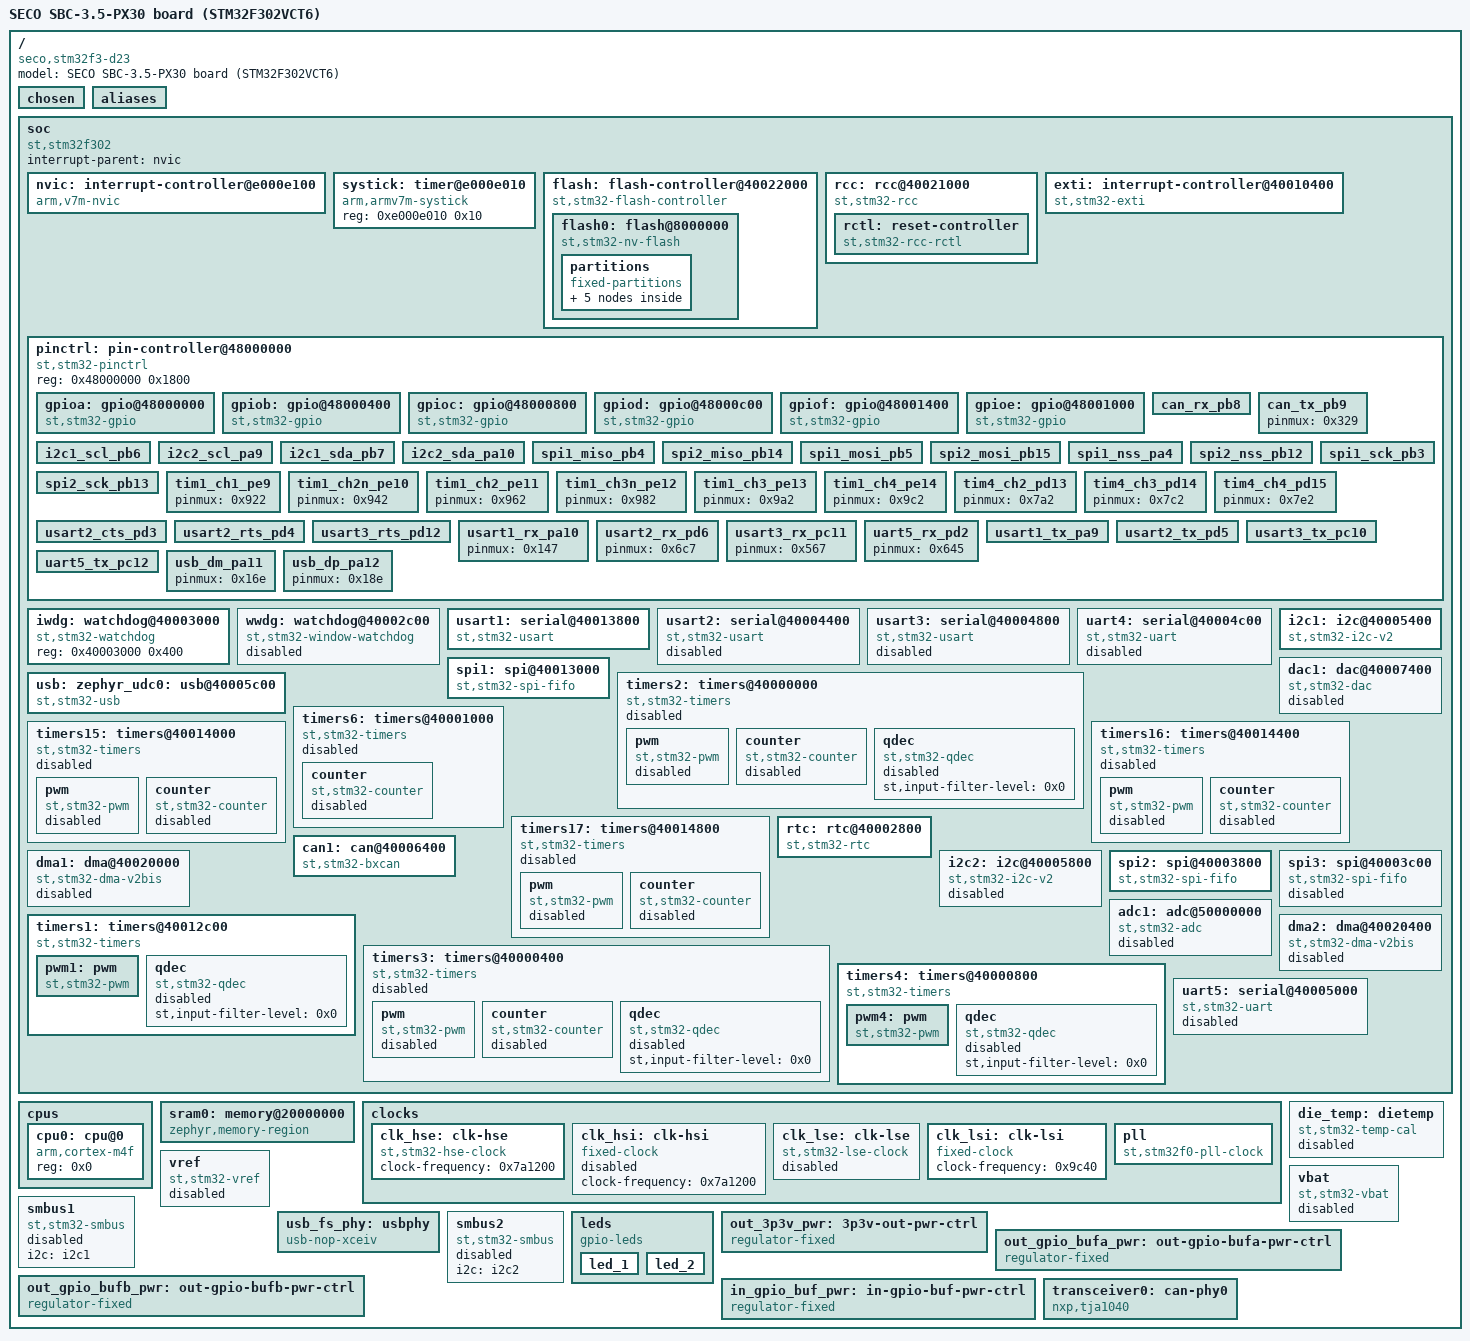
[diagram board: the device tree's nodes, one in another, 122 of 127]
/dts-v1/;

/* node '/' defined in zephyr/dts/common/skeleton.dtsi:9 */
/ {
	#address-cells = < 0x1 >;                          /* in zephyr/dts/common/skeleton.dtsi:10 */
	#size-cells = < 0x1 >;                             /* in zephyr/dts/common/skeleton.dtsi:11 */
	model = "SECO SBC-3.5-PX30 board (STM32F302VCT6)"; /* in zephyr/boards/seco/stm32f3_seco_d23/stm32f3_seco_d23.dts:12 */
	compatible = "seco,stm32f3-d23";                   /* in zephyr/boards/seco/stm32f3_seco_d23/stm32f3_seco_d23.dts:13 */

	/* node '/chosen' defined in zephyr/dts/common/skeleton.dtsi:13 */
	chosen {
		zephyr,flash-controller = &flash;         /* in zephyr/dts/arm/st/f3/stm32f3.dtsi:24 */
		zephyr,console = &usart1;                 /* in zephyr/boards/seco/stm32f3_seco_d23/stm32f3_seco_d23.dts:16 */
		zephyr,code-partition = &slot0_partition; /* in zephyr/boards/seco/stm32f3_seco_d23/stm32f3_seco_d23.dts:17 */
		zephyr,shell-uart = &usart1;              /* in zephyr/boards/seco/stm32f3_seco_d23/stm32f3_seco_d23.dts:18 */
		zephyr,sram = &sram0;                     /* in zephyr/boards/seco/stm32f3_seco_d23/stm32f3_seco_d23.dts:19 */
		zephyr,flash = &flash0;                   /* in zephyr/boards/seco/stm32f3_seco_d23/stm32f3_seco_d23.dts:20 */
		zephyr,canbus = &can1;                    /* in zephyr/boards/seco/stm32f3_seco_d23/stm32f3_seco_d23.dts:21 */
	};

	/* node '/aliases' defined in zephyr/dts/common/skeleton.dtsi:15 */
	aliases {
		led0 = &led_1; /* in zephyr/boards/seco/stm32f3_seco_d23/stm32f3_seco_d23.dts:79 */
		led1 = &led_2; /* in zephyr/boards/seco/stm32f3_seco_d23/stm32f3_seco_d23.dts:80 */
	};

	/* node '/soc' defined in zephyr/dts/arm/armv7-m.dtsi:6 */
	soc {
		#address-cells = < 0x1 >;     /* in zephyr/dts/arm/armv7-m.dtsi:7 */
		#size-cells = < 0x1 >;        /* in zephyr/dts/arm/armv7-m.dtsi:8 */
		interrupt-parent = < &nvic >; /* in zephyr/dts/arm/armv7-m.dtsi:10 */
		ranges;                       /* in zephyr/dts/arm/armv7-m.dtsi:11 */
		compatible = "st,stm32f302",
		             "st,stm32f3",
		             "simple-bus";    /* in zephyr/dts/arm/st/f3/stm32f302.dtsi:12 */

		/* node '/soc/interrupt-controller@e000e100' defined in zephyr/dts/arm/armv7-m.dtsi:13 */
		nvic: interrupt-controller@e000e100 {
			#address-cells = < 0x1 >;            /* in zephyr/dts/arm/armv7-m.dtsi:14 */
			compatible = "arm,v7m-nvic";         /* in zephyr/dts/arm/armv7-m.dtsi:15 */
			reg = < 0xe000e100 0xc00 >;          /* in zephyr/dts/arm/armv7-m.dtsi:16 */
			interrupt-controller;                /* in zephyr/dts/arm/armv7-m.dtsi:17 */
			#interrupt-cells = < 0x2 >;          /* in zephyr/dts/arm/armv7-m.dtsi:18 */
			arm,num-irq-priority-bits = < 0x4 >; /* in zephyr/dts/arm/st/f3/stm32f3.dtsi:456 */
			phandle = < 0x1 >;                   /* in zephyr/dts/arm/armv7-m.dtsi:10 */
		};

		/* node '/soc/timer@e000e010' defined in zephyr/dts/arm/armv7-m.dtsi:21 */
		systick: timer@e000e010 {
			compatible = "arm,armv7m-systick"; /* in zephyr/dts/arm/armv7-m.dtsi:22 */
			reg = < 0xe000e010 0x10 >;         /* in zephyr/dts/arm/armv7-m.dtsi:23 */
		};

		/* node '/soc/flash-controller@40022000' defined in zephyr/dts/arm/st/f3/stm32f3.dtsi:80 */
		flash: flash-controller@40022000 {
			compatible = "st,stm32-flash-controller",
			             "st,stm32f1-flash-controller"; /* in zephyr/dts/arm/st/f3/stm32f3.dtsi:81 */
			reg = < 0x40022000 0x400 >;                 /* in zephyr/dts/arm/st/f3/stm32f3.dtsi:82 */
			interrupts = < 0x4 0x0 >;                   /* in zephyr/dts/arm/st/f3/stm32f3.dtsi:83 */
			clocks = < &rcc 0x14 0x10 >;                /* in zephyr/dts/arm/st/f3/stm32f3.dtsi:84 */
			#address-cells = < 0x1 >;                   /* in zephyr/dts/arm/st/f3/stm32f3.dtsi:86 */
			#size-cells = < 0x1 >;                      /* in zephyr/dts/arm/st/f3/stm32f3.dtsi:87 */

			/* node '/soc/flash-controller@40022000/flash@8000000' defined in zephyr/dts/arm/st/f3/stm32f3.dtsi:89 */
			flash0: flash@8000000 {
				compatible = "st,stm32-nv-flash",
				             "soc-nv-flash";      /* in zephyr/dts/arm/st/f3/stm32f3.dtsi:90 */
				write-block-size = < 0x2 >;       /* in zephyr/dts/arm/st/f3/stm32f3.dtsi:92 */
				erase-block-size = < 0x800 >;     /* in zephyr/dts/arm/st/f3/stm32f3.dtsi:93 */
				max-erase-time = < 0x28 >;        /* in zephyr/dts/arm/st/f3/stm32f3.dtsi:95 */
				reg = < 0x8000000 0x40000 >;      /* in zephyr/dts/arm/st/f3/stm32f302Xc.dtsi:18 */

				/* node '/soc/flash-controller@40022000/flash@8000000/partitions' defined in zephyr/boards/seco/stm32f3_seco_d23/stm32f3_seco_d23.dts:187 */
				partitions {
					compatible = "fixed-partitions"; /* in zephyr/boards/seco/stm32f3_seco_d23/stm32f3_seco_d23.dts:188 */
					#address-cells = < 0x1 >;        /* in zephyr/boards/seco/stm32f3_seco_d23/stm32f3_seco_d23.dts:189 */
					#size-cells = < 0x1 >;           /* in zephyr/boards/seco/stm32f3_seco_d23/stm32f3_seco_d23.dts:190 */

					/* node '/soc/flash-controller@40022000/flash@8000000/partitions/partition@0' defined in zephyr/boards/seco/stm32f3_seco_d23/stm32f3_seco_d23.dts:192 */
					boot_partition: partition@0 {
						label = "mcuboot";     /* in zephyr/boards/seco/stm32f3_seco_d23/stm32f3_seco_d23.dts:193 */
						reg = < 0x0 0x10000 >; /* in zephyr/boards/seco/stm32f3_seco_d23/stm32f3_seco_d23.dts:194 */
						read-only;             /* in zephyr/boards/seco/stm32f3_seco_d23/stm32f3_seco_d23.dts:195 */
					};

					/* node '/soc/flash-controller@40022000/flash@8000000/partitions/partition@20000' defined in zephyr/boards/seco/stm32f3_seco_d23/stm32f3_seco_d23.dts:203 */
					slot0_partition: partition@20000 {
						label = "image-0";        /* in zephyr/boards/seco/stm32f3_seco_d23/stm32f3_seco_d23.dts:204 */
						reg = < 0x20000 0x8000 >; /* in zephyr/boards/seco/stm32f3_seco_d23/stm32f3_seco_d23.dts:205 */
					};

					/* node '/soc/flash-controller@40022000/flash@8000000/partitions/partition@28000' defined in zephyr/boards/seco/stm32f3_seco_d23/stm32f3_seco_d23.dts:208 */
					slot1_partition: partition@28000 {
						label = "image-1";        /* in zephyr/boards/seco/stm32f3_seco_d23/stm32f3_seco_d23.dts:209 */
						reg = < 0x28000 0x8000 >; /* in zephyr/boards/seco/stm32f3_seco_d23/stm32f3_seco_d23.dts:210 */
					};

					/* node '/soc/flash-controller@40022000/flash@8000000/partitions/partition@30000' defined in zephyr/boards/seco/stm32f3_seco_d23/stm32f3_seco_d23.dts:213 */
					storage_partition: partition@30000 {
						label = "storage";        /* in zephyr/boards/seco/stm32f3_seco_d23/stm32f3_seco_d23.dts:214 */
						reg = < 0x30000 0x2000 >; /* in zephyr/boards/seco/stm32f3_seco_d23/stm32f3_seco_d23.dts:215 */
					};

					/* node '/soc/flash-controller@40022000/flash@8000000/partitions/partition@32000' defined in zephyr/boards/seco/stm32f3_seco_d23/stm32f3_seco_d23.dts:218 */
					scratch_partition: partition@32000 {
						label = "image-scratch";  /* in zephyr/boards/seco/stm32f3_seco_d23/stm32f3_seco_d23.dts:219 */
						reg = < 0x32000 0x8000 >; /* in zephyr/boards/seco/stm32f3_seco_d23/stm32f3_seco_d23.dts:220 */
					};
				};
			};
		};

		/* node '/soc/rcc@40021000' defined in zephyr/dts/arm/st/f3/stm32f3.dtsi:99 */
		rcc: rcc@40021000 {
			compatible = "st,stm32-rcc";     /* in zephyr/dts/arm/st/f3/stm32f3.dtsi:100 */
			#clock-cells = < 0x2 >;          /* in zephyr/dts/arm/st/f3/stm32f3.dtsi:101 */
			reg = < 0x40021000 0x400 >;      /* in zephyr/dts/arm/st/f3/stm32f3.dtsi:102 */
			clocks = < &pll >;               /* in zephyr/boards/seco/stm32f3_seco_d23/stm32f3_seco_d23.dts:101 */
			clock-frequency = < 0x44aa200 >; /* in zephyr/boards/seco/stm32f3_seco_d23/stm32f3_seco_d23.dts:102 */
			ahb-prescaler = < 0x1 >;         /* in zephyr/boards/seco/stm32f3_seco_d23/stm32f3_seco_d23.dts:103 */
			apb1-prescaler = < 0x2 >;        /* in zephyr/boards/seco/stm32f3_seco_d23/stm32f3_seco_d23.dts:104 */
			apb2-prescaler = < 0x1 >;        /* in zephyr/boards/seco/stm32f3_seco_d23/stm32f3_seco_d23.dts:105 */
			status = "okay";                 /* in zephyr/boards/seco/stm32f3_seco_d23/stm32f3_seco_d23.dts:106 */
			phandle = < 0x2 >;               /* in zephyr/dts/arm/st/f3/stm32f3.dtsi:84 */

			/* node '/soc/rcc@40021000/reset-controller' defined in zephyr/dts/arm/st/f3/stm32f3.dtsi:104 */
			rctl: reset-controller {
				compatible = "st,stm32-rcc-rctl"; /* in zephyr/dts/arm/st/f3/stm32f3.dtsi:105 */
				#reset-cells = < 0x1 >;           /* in zephyr/dts/arm/st/f3/stm32f3.dtsi:106 */
				phandle = < 0x4 >;                /* in zephyr/dts/arm/st/f3/stm32f3.dtsi:191 */
			};
		};

		/* node '/soc/interrupt-controller@40010400' defined in zephyr/dts/arm/st/f3/stm32f3.dtsi:110 */
		exti: interrupt-controller@40010400 {
			compatible = "st,stm32-exti";  /* in zephyr/dts/arm/st/f3/stm32f3.dtsi:111 */
			interrupt-controller;          /* in zephyr/dts/arm/st/f3/stm32f3.dtsi:112 */
			#interrupt-cells = < 0x1 >;    /* in zephyr/dts/arm/st/f3/stm32f3.dtsi:113 */
			#address-cells = < 0x0 >;      /* in zephyr/dts/arm/st/f3/stm32f3.dtsi:114 */
			reg = < 0x40010400 0x400 >;    /* in zephyr/dts/arm/st/f3/stm32f3.dtsi:115 */
			clocks = < &rcc 0x18 0x1 >;    /* in zephyr/dts/arm/st/f3/stm32f3.dtsi:116 */
			num-lines = < 0x20 >;          /* in zephyr/dts/arm/st/f3/stm32f3.dtsi:117 */
			interrupts = < 0x6 0x0 >,
			             < 0x7 0x0 >,
			             < 0x8 0x0 >,
			             < 0x9 0x0 >,
			             < 0xa 0x0 >,
			             < 0x17 0x0 >,
			             < 0x28 0x0 >;     /* in zephyr/dts/arm/st/f3/stm32f3.dtsi:118 */
			interrupt-names = "line0",
			                  "line1",
			                  "line2",
			                  "line3",
			                  "line4",
			                  "line5-9",
			                  "line10-15"; /* in zephyr/dts/arm/st/f3/stm32f3.dtsi:120 */
			line-ranges = < 0x0 0x1 >,
			              < 0x1 0x1 >,
			              < 0x2 0x1 >,
			              < 0x3 0x1 >,
			              < 0x4 0x1 >,
			              < 0x5 0x5 >,
			              < 0xa 0x6 >;     /* in zephyr/dts/arm/st/f3/stm32f3.dtsi:122 */
		};

		/* node '/soc/pin-controller@48000000' defined in zephyr/dts/arm/st/f3/stm32f3.dtsi:126 */
		pinctrl: pin-controller@48000000 {
			compatible = "st,stm32-pinctrl"; /* in zephyr/dts/arm/st/f3/stm32f3.dtsi:127 */
			#address-cells = < 0x1 >;        /* in zephyr/dts/arm/st/f3/stm32f3.dtsi:128 */
			#size-cells = < 0x1 >;           /* in zephyr/dts/arm/st/f3/stm32f3.dtsi:129 */
			reg = < 0x48000000 0x1800 >;     /* in zephyr/dts/arm/st/f3/stm32f3.dtsi:130 */

			/* node '/soc/pin-controller@48000000/gpio@48000000' defined in zephyr/dts/arm/st/f3/stm32f3.dtsi:132 */
			gpioa: gpio@48000000 {
				compatible = "st,stm32-gpio";   /* in zephyr/dts/arm/st/f3/stm32f3.dtsi:133 */
				gpio-controller;                /* in zephyr/dts/arm/st/f3/stm32f3.dtsi:134 */
				#gpio-cells = < 0x2 >;          /* in zephyr/dts/arm/st/f3/stm32f3.dtsi:135 */
				reg = < 0x48000000 0x400 >;     /* in zephyr/dts/arm/st/f3/stm32f3.dtsi:136 */
				clocks = < &rcc 0x14 0x20000 >; /* in zephyr/dts/arm/st/f3/stm32f3.dtsi:137 */
			};

			/* node '/soc/pin-controller@48000000/gpio@48000400' defined in zephyr/dts/arm/st/f3/stm32f3.dtsi:140 */
			gpiob: gpio@48000400 {
				compatible = "st,stm32-gpio";   /* in zephyr/dts/arm/st/f3/stm32f3.dtsi:141 */
				gpio-controller;                /* in zephyr/dts/arm/st/f3/stm32f3.dtsi:142 */
				#gpio-cells = < 0x2 >;          /* in zephyr/dts/arm/st/f3/stm32f3.dtsi:143 */
				reg = < 0x48000400 0x400 >;     /* in zephyr/dts/arm/st/f3/stm32f3.dtsi:144 */
				clocks = < &rcc 0x14 0x40000 >; /* in zephyr/dts/arm/st/f3/stm32f3.dtsi:145 */
			};

			/* node '/soc/pin-controller@48000000/gpio@48000800' defined in zephyr/dts/arm/st/f3/stm32f3.dtsi:148 */
			gpioc: gpio@48000800 {
				compatible = "st,stm32-gpio";   /* in zephyr/dts/arm/st/f3/stm32f3.dtsi:149 */
				gpio-controller;                /* in zephyr/dts/arm/st/f3/stm32f3.dtsi:150 */
				#gpio-cells = < 0x2 >;          /* in zephyr/dts/arm/st/f3/stm32f3.dtsi:151 */
				reg = < 0x48000800 0x400 >;     /* in zephyr/dts/arm/st/f3/stm32f3.dtsi:152 */
				clocks = < &rcc 0x14 0x80000 >; /* in zephyr/dts/arm/st/f3/stm32f3.dtsi:153 */
			};

			/* node '/soc/pin-controller@48000000/gpio@48000c00' defined in zephyr/dts/arm/st/f3/stm32f3.dtsi:156 */
			gpiod: gpio@48000c00 {
				compatible = "st,stm32-gpio";    /* in zephyr/dts/arm/st/f3/stm32f3.dtsi:157 */
				gpio-controller;                 /* in zephyr/dts/arm/st/f3/stm32f3.dtsi:158 */
				#gpio-cells = < 0x2 >;           /* in zephyr/dts/arm/st/f3/stm32f3.dtsi:159 */
				reg = < 0x48000c00 0x400 >;      /* in zephyr/dts/arm/st/f3/stm32f3.dtsi:160 */
				clocks = < &rcc 0x14 0x100000 >; /* in zephyr/dts/arm/st/f3/stm32f3.dtsi:161 */
				phandle = < 0x2f >;              /* in zephyr/boards/seco/stm32f3_seco_d23/stm32f3_seco_d23.dts:28 */
			};

			/* node '/soc/pin-controller@48000000/gpio@48001400' defined in zephyr/dts/arm/st/f3/stm32f3.dtsi:164 */
			gpiof: gpio@48001400 {
				compatible = "st,stm32-gpio";    /* in zephyr/dts/arm/st/f3/stm32f3.dtsi:165 */
				gpio-controller;                 /* in zephyr/dts/arm/st/f3/stm32f3.dtsi:166 */
				#gpio-cells = < 0x2 >;           /* in zephyr/dts/arm/st/f3/stm32f3.dtsi:167 */
				reg = < 0x48001400 0x400 >;      /* in zephyr/dts/arm/st/f3/stm32f3.dtsi:168 */
				clocks = < &rcc 0x14 0x400000 >; /* in zephyr/dts/arm/st/f3/stm32f3.dtsi:169 */
				phandle = < 0x31 >;              /* in zephyr/boards/seco/stm32f3_seco_d23/stm32f3_seco_d23.dts:50 */
			};

			/* node '/soc/pin-controller@48000000/gpio@48001000' defined in zephyr/dts/arm/st/f3/stm32f302Xc.dtsi:98 */
			gpioe: gpio@48001000 {
				compatible = "st,stm32-gpio";    /* in zephyr/dts/arm/st/f3/stm32f302Xc.dtsi:99 */
				gpio-controller;                 /* in zephyr/dts/arm/st/f3/stm32f302Xc.dtsi:100 */
				#gpio-cells = < 0x2 >;           /* in zephyr/dts/arm/st/f3/stm32f302Xc.dtsi:101 */
				reg = < 0x48001000 0x400 >;      /* in zephyr/dts/arm/st/f3/stm32f302Xc.dtsi:102 */
				clocks = < &rcc 0x14 0x200000 >; /* in zephyr/dts/arm/st/f3/stm32f302Xc.dtsi:103 */
				phandle = < 0x30 >;              /* in zephyr/boards/seco/stm32f3_seco_d23/stm32f3_seco_d23.dts:41 */
			};

			/* node '/soc/pin-controller@48000000/can_rx_pb8' defined in modules/hal/stm32/dts/st/f3/stm32f302v(b-c)tx-pinctrl.dtsi:460 */
			can_rx_pb8: can_rx_pb8 {
				pinmux = < 0x309 >; /* in modules/hal/stm32/dts/st/f3/stm32f302v(b-c)tx-pinctrl.dtsi:461 */
				bias-pull-up;       /* in modules/hal/stm32/dts/st/f3/stm32f302v(b-c)tx-pinctrl.dtsi:462 */
				phandle = < 0x17 >; /* in zephyr/boards/seco/stm32f3_seco_d23/stm32f3_seco_d23.dts:180 */
			};

			/* node '/soc/pin-controller@48000000/can_tx_pb9' defined in modules/hal/stm32/dts/st/f3/stm32f302v(b-c)tx-pinctrl.dtsi:476 */
			can_tx_pb9: can_tx_pb9 {
				pinmux = < 0x329 >; /* in modules/hal/stm32/dts/st/f3/stm32f302v(b-c)tx-pinctrl.dtsi:477 */
				phandle = < 0x18 >; /* in zephyr/boards/seco/stm32f3_seco_d23/stm32f3_seco_d23.dts:180 */
			};

			/* node '/soc/pin-controller@48000000/i2c1_scl_pb6' defined in modules/hal/stm32/dts/st/f3/stm32f302v(b-c)tx-pinctrl.dtsi:634 */
			i2c1_scl_pb6: i2c1_scl_pb6 {
				pinmux = < 0x2c4 >; /* in modules/hal/stm32/dts/st/f3/stm32f302v(b-c)tx-pinctrl.dtsi:635 */
				bias-pull-up;       /* in modules/hal/stm32/dts/st/f3/stm32f302v(b-c)tx-pinctrl.dtsi:636 */
				drive-open-drain;   /* in modules/hal/stm32/dts/st/f3/stm32f302v(b-c)tx-pinctrl.dtsi:637 */
				phandle = < 0xe >;  /* in zephyr/boards/seco/stm32f3_seco_d23/stm32f3_seco_d23.dts:140 */
			};

			/* node '/soc/pin-controller@48000000/i2c2_scl_pa9' defined in modules/hal/stm32/dts/st/f3/stm32f302v(b-c)tx-pinctrl.dtsi:646 */
			i2c2_scl_pa9: i2c2_scl_pa9 {
				pinmux = < 0x124 >; /* in modules/hal/stm32/dts/st/f3/stm32f302v(b-c)tx-pinctrl.dtsi:647 */
				bias-pull-up;       /* in modules/hal/stm32/dts/st/f3/stm32f302v(b-c)tx-pinctrl.dtsi:648 */
				drive-open-drain;   /* in modules/hal/stm32/dts/st/f3/stm32f302v(b-c)tx-pinctrl.dtsi:649 */
				phandle = < 0x1a >; /* in zephyr/boards/seco/stm32f3_seco_d23/stm32f3_seco_d23.dts:148 */
			};

			/* node '/soc/pin-controller@48000000/i2c1_sda_pb7' defined in modules/hal/stm32/dts/st/f3/stm32f302v(b-c)tx-pinctrl.dtsi:672 */
			i2c1_sda_pb7: i2c1_sda_pb7 {
				pinmux = < 0x2e4 >; /* in modules/hal/stm32/dts/st/f3/stm32f302v(b-c)tx-pinctrl.dtsi:673 */
				bias-pull-up;       /* in modules/hal/stm32/dts/st/f3/stm32f302v(b-c)tx-pinctrl.dtsi:674 */
				drive-open-drain;   /* in modules/hal/stm32/dts/st/f3/stm32f302v(b-c)tx-pinctrl.dtsi:675 */
				phandle = < 0xf >;  /* in zephyr/boards/seco/stm32f3_seco_d23/stm32f3_seco_d23.dts:140 */
			};

			/* node '/soc/pin-controller@48000000/i2c2_sda_pa10' defined in modules/hal/stm32/dts/st/f3/stm32f302v(b-c)tx-pinctrl.dtsi:684 */
			i2c2_sda_pa10: i2c2_sda_pa10 {
				pinmux = < 0x144 >; /* in modules/hal/stm32/dts/st/f3/stm32f302v(b-c)tx-pinctrl.dtsi:685 */
				bias-pull-up;       /* in modules/hal/stm32/dts/st/f3/stm32f302v(b-c)tx-pinctrl.dtsi:686 */
				drive-open-drain;   /* in modules/hal/stm32/dts/st/f3/stm32f302v(b-c)tx-pinctrl.dtsi:687 */
				phandle = < 0x1b >; /* in zephyr/boards/seco/stm32f3_seco_d23/stm32f3_seco_d23.dts:148 */
			};

			/* node '/soc/pin-controller@48000000/spi1_miso_pb4' defined in modules/hal/stm32/dts/st/f3/stm32f302v(b-c)tx-pinctrl.dtsi:874 */
			spi1_miso_pb4: spi1_miso_pb4 {
				pinmux = < 0x285 >; /* in modules/hal/stm32/dts/st/f3/stm32f302v(b-c)tx-pinctrl.dtsi:875 */
				bias-pull-down;     /* in modules/hal/stm32/dts/st/f3/stm32f302v(b-c)tx-pinctrl.dtsi:876 */
				phandle = < 0x12 >; /* in zephyr/boards/seco/stm32f3_seco_d23/stm32f3_seco_d23.dts:154 */
			};

			/* node '/soc/pin-controller@48000000/spi2_miso_pb14' defined in modules/hal/stm32/dts/st/f3/stm32f302v(b-c)tx-pinctrl.dtsi:879 */
			spi2_miso_pb14: spi2_miso_pb14 {
				pinmux = < 0x3c5 >; /* in modules/hal/stm32/dts/st/f3/stm32f302v(b-c)tx-pinctrl.dtsi:880 */
				bias-pull-down;     /* in modules/hal/stm32/dts/st/f3/stm32f302v(b-c)tx-pinctrl.dtsi:881 */
				phandle = < 0x1e >; /* in zephyr/boards/seco/stm32f3_seco_d23/stm32f3_seco_d23.dts:161 */
			};

			/* node '/soc/pin-controller@48000000/spi1_mosi_pb5' defined in modules/hal/stm32/dts/st/f3/stm32f302v(b-c)tx-pinctrl.dtsi:901 */
			spi1_mosi_pb5: spi1_mosi_pb5 {
				pinmux = < 0x2a5 >; /* in modules/hal/stm32/dts/st/f3/stm32f302v(b-c)tx-pinctrl.dtsi:902 */
				bias-pull-down;     /* in modules/hal/stm32/dts/st/f3/stm32f302v(b-c)tx-pinctrl.dtsi:903 */
				phandle = < 0x13 >; /* in zephyr/boards/seco/stm32f3_seco_d23/stm32f3_seco_d23.dts:154 */
			};

			/* node '/soc/pin-controller@48000000/spi2_mosi_pb15' defined in modules/hal/stm32/dts/st/f3/stm32f302v(b-c)tx-pinctrl.dtsi:906 */
			spi2_mosi_pb15: spi2_mosi_pb15 {
				pinmux = < 0x3e5 >; /* in modules/hal/stm32/dts/st/f3/stm32f302v(b-c)tx-pinctrl.dtsi:907 */
				bias-pull-down;     /* in modules/hal/stm32/dts/st/f3/stm32f302v(b-c)tx-pinctrl.dtsi:908 */
				phandle = < 0x1f >; /* in zephyr/boards/seco/stm32f3_seco_d23/stm32f3_seco_d23.dts:161 */
			};

			/* node '/soc/pin-controller@48000000/spi1_nss_pa4' defined in modules/hal/stm32/dts/st/f3/stm32f302v(b-c)tx-pinctrl.dtsi:923 */
			spi1_nss_pa4: spi1_nss_pa4 {
				pinmux = < 0x85 >;  /* in modules/hal/stm32/dts/st/f3/stm32f302v(b-c)tx-pinctrl.dtsi:924 */
				bias-pull-up;       /* in modules/hal/stm32/dts/st/f3/stm32f302v(b-c)tx-pinctrl.dtsi:925 */
				phandle = < 0x10 >; /* in zephyr/boards/seco/stm32f3_seco_d23/stm32f3_seco_d23.dts:154 */
			};

			/* node '/soc/pin-controller@48000000/spi2_nss_pb12' defined in modules/hal/stm32/dts/st/f3/stm32f302v(b-c)tx-pinctrl.dtsi:933 */
			spi2_nss_pb12: spi2_nss_pb12 {
				pinmux = < 0x385 >; /* in modules/hal/stm32/dts/st/f3/stm32f302v(b-c)tx-pinctrl.dtsi:934 */
				bias-pull-up;       /* in modules/hal/stm32/dts/st/f3/stm32f302v(b-c)tx-pinctrl.dtsi:935 */
				phandle = < 0x1c >; /* in zephyr/boards/seco/stm32f3_seco_d23/stm32f3_seco_d23.dts:161 */
			};

			/* node '/soc/pin-controller@48000000/spi1_sck_pb3' defined in modules/hal/stm32/dts/st/f3/stm32f302v(b-c)tx-pinctrl.dtsi:961 */
			spi1_sck_pb3: spi1_sck_pb3 {
				pinmux = < 0x265 >;            /* in modules/hal/stm32/dts/st/f3/stm32f302v(b-c)tx-pinctrl.dtsi:962 */
				bias-pull-down;                /* in modules/hal/stm32/dts/st/f3/stm32f302v(b-c)tx-pinctrl.dtsi:963 */
				slew-rate = "very-high-speed"; /* in modules/hal/stm32/dts/st/f3/stm32f302v(b-c)tx-pinctrl.dtsi:964 */
				phandle = < 0x11 >;            /* in zephyr/boards/seco/stm32f3_seco_d23/stm32f3_seco_d23.dts:154 */
			};

			/* node '/soc/pin-controller@48000000/spi2_sck_pb13' defined in modules/hal/stm32/dts/st/f3/stm32f302v(b-c)tx-pinctrl.dtsi:967 */
			spi2_sck_pb13: spi2_sck_pb13 {
				pinmux = < 0x3a5 >;            /* in modules/hal/stm32/dts/st/f3/stm32f302v(b-c)tx-pinctrl.dtsi:968 */
				bias-pull-down;                /* in modules/hal/stm32/dts/st/f3/stm32f302v(b-c)tx-pinctrl.dtsi:969 */
				slew-rate = "very-high-speed"; /* in modules/hal/stm32/dts/st/f3/stm32f302v(b-c)tx-pinctrl.dtsi:970 */
				phandle = < 0x1d >;            /* in zephyr/boards/seco/stm32f3_seco_d23/stm32f3_seco_d23.dts:161 */
			};

			/* node '/soc/pin-controller@48000000/tim1_ch1_pe9' defined in modules/hal/stm32/dts/st/f3/stm32f302v(b-c)tx-pinctrl.dtsi:1109 */
			tim1_ch1_pe9: tim1_ch1_pe9 {
				pinmux = < 0x922 >; /* in modules/hal/stm32/dts/st/f3/stm32f302v(b-c)tx-pinctrl.dtsi:1110 */
				phandle = < 0x20 >; /* in zephyr/boards/seco/stm32f3_seco_d23/stm32f3_seco_d23.dts:234 */
			};

			/* node '/soc/pin-controller@48000000/tim1_ch2n_pe10' defined in modules/hal/stm32/dts/st/f3/stm32f302v(b-c)tx-pinctrl.dtsi:1113 */
			tim1_ch2n_pe10: tim1_ch2n_pe10 {
				pinmux = < 0x942 >; /* in modules/hal/stm32/dts/st/f3/stm32f302v(b-c)tx-pinctrl.dtsi:1114 */
				phandle = < 0x21 >; /* in zephyr/boards/seco/stm32f3_seco_d23/stm32f3_seco_d23.dts:234 */
			};

			/* node '/soc/pin-controller@48000000/tim1_ch2_pe11' defined in modules/hal/stm32/dts/st/f3/stm32f302v(b-c)tx-pinctrl.dtsi:1117 */
			tim1_ch2_pe11: tim1_ch2_pe11 {
				pinmux = < 0x962 >; /* in modules/hal/stm32/dts/st/f3/stm32f302v(b-c)tx-pinctrl.dtsi:1118 */
				phandle = < 0x22 >; /* in zephyr/boards/seco/stm32f3_seco_d23/stm32f3_seco_d23.dts:234 */
			};

			/* node '/soc/pin-controller@48000000/tim1_ch3n_pe12' defined in modules/hal/stm32/dts/st/f3/stm32f302v(b-c)tx-pinctrl.dtsi:1121 */
			tim1_ch3n_pe12: tim1_ch3n_pe12 {
				pinmux = < 0x982 >; /* in modules/hal/stm32/dts/st/f3/stm32f302v(b-c)tx-pinctrl.dtsi:1122 */
				phandle = < 0x23 >; /* in zephyr/boards/seco/stm32f3_seco_d23/stm32f3_seco_d23.dts:234 */
			};

			/* node '/soc/pin-controller@48000000/tim1_ch3_pe13' defined in modules/hal/stm32/dts/st/f3/stm32f302v(b-c)tx-pinctrl.dtsi:1125 */
			tim1_ch3_pe13: tim1_ch3_pe13 {
				pinmux = < 0x9a2 >; /* in modules/hal/stm32/dts/st/f3/stm32f302v(b-c)tx-pinctrl.dtsi:1126 */
				phandle = < 0x24 >; /* in zephyr/boards/seco/stm32f3_seco_d23/stm32f3_seco_d23.dts:234 */
			};

			/* node '/soc/pin-controller@48000000/tim1_ch4_pe14' defined in modules/hal/stm32/dts/st/f3/stm32f302v(b-c)tx-pinctrl.dtsi:1129 */
			tim1_ch4_pe14: tim1_ch4_pe14 {
				pinmux = < 0x9c2 >; /* in modules/hal/stm32/dts/st/f3/stm32f302v(b-c)tx-pinctrl.dtsi:1130 */
				phandle = < 0x25 >; /* in zephyr/boards/seco/stm32f3_seco_d23/stm32f3_seco_d23.dts:234 */
			};

			/* node '/soc/pin-controller@48000000/tim4_ch2_pd13' defined in modules/hal/stm32/dts/st/f3/stm32f302v(b-c)tx-pinctrl.dtsi:1293 */
			tim4_ch2_pd13: tim4_ch2_pd13 {
				pinmux = < 0x7a2 >; /* in modules/hal/stm32/dts/st/f3/stm32f302v(b-c)tx-pinctrl.dtsi:1294 */
				phandle = < 0x26 >; /* in zephyr/boards/seco/stm32f3_seco_d23/stm32f3_seco_d23.dts:246 */
			};

			/* node '/soc/pin-controller@48000000/tim4_ch3_pd14' defined in modules/hal/stm32/dts/st/f3/stm32f302v(b-c)tx-pinctrl.dtsi:1297 */
			tim4_ch3_pd14: tim4_ch3_pd14 {
				pinmux = < 0x7c2 >; /* in modules/hal/stm32/dts/st/f3/stm32f302v(b-c)tx-pinctrl.dtsi:1298 */
				phandle = < 0x27 >; /* in zephyr/boards/seco/stm32f3_seco_d23/stm32f3_seco_d23.dts:246 */
			};

			/* node '/soc/pin-controller@48000000/tim4_ch4_pd15' defined in modules/hal/stm32/dts/st/f3/stm32f302v(b-c)tx-pinctrl.dtsi:1301 */
			tim4_ch4_pd15: tim4_ch4_pd15 {
				pinmux = < 0x7e2 >; /* in modules/hal/stm32/dts/st/f3/stm32f302v(b-c)tx-pinctrl.dtsi:1302 */
				phandle = < 0x28 >; /* in zephyr/boards/seco/stm32f3_seco_d23/stm32f3_seco_d23.dts:246 */
			};

			/* node '/soc/pin-controller@48000000/usart2_cts_pd3' defined in modules/hal/stm32/dts/st/f3/stm32f302v(b-c)tx-pinctrl.dtsi:1539 */
			usart2_cts_pd3: usart2_cts_pd3 {
				pinmux = < 0x667 >; /* in modules/hal/stm32/dts/st/f3/stm32f302v(b-c)tx-pinctrl.dtsi:1540 */
				bias-pull-up;       /* in modules/hal/stm32/dts/st/f3/stm32f302v(b-c)tx-pinctrl.dtsi:1541 */
				phandle = < 0x9 >;  /* in zephyr/boards/seco/stm32f3_seco_d23/stm32f3_seco_d23.dts:119 */
			};

			/* node '/soc/pin-controller@48000000/usart2_rts_pd4' defined in modules/hal/stm32/dts/st/f3/stm32f302v(b-c)tx-pinctrl.dtsi:1603 */
			usart2_rts_pd4: usart2_rts_pd4 {
				pinmux = < 0x687 >; /* in modules/hal/stm32/dts/st/f3/stm32f302v(b-c)tx-pinctrl.dtsi:1604 */
				drive-push-pull;    /* in modules/hal/stm32/dts/st/f3/stm32f302v(b-c)tx-pinctrl.dtsi:1605 */
				phandle = < 0xa >;  /* in zephyr/boards/seco/stm32f3_seco_d23/stm32f3_seco_d23.dts:119 */
			};

			/* node '/soc/pin-controller@48000000/usart3_rts_pd12' defined in modules/hal/stm32/dts/st/f3/stm32f302v(b-c)tx-pinctrl.dtsi:1613 */
			usart3_rts_pd12: usart3_rts_pd12 {
				pinmux = < 0x787 >; /* in modules/hal/stm32/dts/st/f3/stm32f302v(b-c)tx-pinctrl.dtsi:1614 */
				drive-push-pull;    /* in modules/hal/stm32/dts/st/f3/stm32f302v(b-c)tx-pinctrl.dtsi:1615 */
				phandle = < 0xd >;  /* in zephyr/boards/seco/stm32f3_seco_d23/stm32f3_seco_d23.dts:127 */
			};

			/* node '/soc/pin-controller@48000000/usart1_rx_pa10' defined in modules/hal/stm32/dts/st/f3/stm32f302v(b-c)tx-pinctrl.dtsi:1625 */
			usart1_rx_pa10: usart1_rx_pa10 {
				pinmux = < 0x147 >; /* in modules/hal/stm32/dts/st/f3/stm32f302v(b-c)tx-pinctrl.dtsi:1626 */
				phandle = < 0x6 >;  /* in zephyr/boards/seco/stm32f3_seco_d23/stm32f3_seco_d23.dts:111 */
			};

			/* node '/soc/pin-controller@48000000/usart2_rx_pd6' defined in modules/hal/stm32/dts/st/f3/stm32f302v(b-c)tx-pinctrl.dtsi:1653 */
			usart2_rx_pd6: usart2_rx_pd6 {
				pinmux = < 0x6c7 >; /* in modules/hal/stm32/dts/st/f3/stm32f302v(b-c)tx-pinctrl.dtsi:1654 */
				phandle = < 0x8 >;  /* in zephyr/boards/seco/stm32f3_seco_d23/stm32f3_seco_d23.dts:119 */
			};

			/* node '/soc/pin-controller@48000000/usart3_rx_pc11' defined in modules/hal/stm32/dts/st/f3/stm32f302v(b-c)tx-pinctrl.dtsi:1661 */
			usart3_rx_pc11: usart3_rx_pc11 {
				pinmux = < 0x567 >; /* in modules/hal/stm32/dts/st/f3/stm32f302v(b-c)tx-pinctrl.dtsi:1662 */
				phandle = < 0xc >;  /* in zephyr/boards/seco/stm32f3_seco_d23/stm32f3_seco_d23.dts:127 */
			};

			/* node '/soc/pin-controller@48000000/uart5_rx_pd2' defined in modules/hal/stm32/dts/st/f3/stm32f302v(b-c)tx-pinctrl.dtsi:1677 */
			uart5_rx_pd2: uart5_rx_pd2 {
				pinmux = < 0x645 >; /* in modules/hal/stm32/dts/st/f3/stm32f302v(b-c)tx-pinctrl.dtsi:1678 */
				phandle = < 0x2a >; /* in zephyr/boards/seco/stm32f3_seco_d23/stm32f3_seco_d23.dts:134 */
			};

			/* node '/soc/pin-controller@48000000/usart1_tx_pa9' defined in modules/hal/stm32/dts/st/f3/stm32f302v(b-c)tx-pinctrl.dtsi:1683 */
			usart1_tx_pa9: usart1_tx_pa9 {
				pinmux = < 0x127 >; /* in modules/hal/stm32/dts/st/f3/stm32f302v(b-c)tx-pinctrl.dtsi:1684 */
				bias-pull-up;       /* in modules/hal/stm32/dts/st/f3/stm32f302v(b-c)tx-pinctrl.dtsi:1685 */
				phandle = < 0x5 >;  /* in zephyr/boards/seco/stm32f3_seco_d23/stm32f3_seco_d23.dts:111 */
			};

			/* node '/soc/pin-controller@48000000/usart2_tx_pd5' defined in modules/hal/stm32/dts/st/f3/stm32f302v(b-c)tx-pinctrl.dtsi:1718 */
			usart2_tx_pd5: usart2_tx_pd5 {
				pinmux = < 0x6a7 >; /* in modules/hal/stm32/dts/st/f3/stm32f302v(b-c)tx-pinctrl.dtsi:1719 */
				bias-pull-up;       /* in modules/hal/stm32/dts/st/f3/stm32f302v(b-c)tx-pinctrl.dtsi:1720 */
				phandle = < 0x7 >;  /* in zephyr/boards/seco/stm32f3_seco_d23/stm32f3_seco_d23.dts:119 */
			};

			/* node '/soc/pin-controller@48000000/usart3_tx_pc10' defined in modules/hal/stm32/dts/st/f3/stm32f302v(b-c)tx-pinctrl.dtsi:1728 */
			usart3_tx_pc10: usart3_tx_pc10 {
				pinmux = < 0x547 >; /* in modules/hal/stm32/dts/st/f3/stm32f302v(b-c)tx-pinctrl.dtsi:1729 */
				bias-pull-up;       /* in modules/hal/stm32/dts/st/f3/stm32f302v(b-c)tx-pinctrl.dtsi:1730 */
				phandle = < 0xb >;  /* in zephyr/boards/seco/stm32f3_seco_d23/stm32f3_seco_d23.dts:127 */
			};

			/* node '/soc/pin-controller@48000000/uart5_tx_pc12' defined in modules/hal/stm32/dts/st/f3/stm32f302v(b-c)tx-pinctrl.dtsi:1743 */
			uart5_tx_pc12: uart5_tx_pc12 {
				pinmux = < 0x585 >; /* in modules/hal/stm32/dts/st/f3/stm32f302v(b-c)tx-pinctrl.dtsi:1744 */
				bias-pull-up;       /* in modules/hal/stm32/dts/st/f3/stm32f302v(b-c)tx-pinctrl.dtsi:1745 */
				phandle = < 0x29 >; /* in zephyr/boards/seco/stm32f3_seco_d23/stm32f3_seco_d23.dts:134 */
			};

			/* node '/soc/pin-controller@48000000/usb_dm_pa11' defined in modules/hal/stm32/dts/st/f3/stm32f302v(b-c)tx-pinctrl.dtsi:1750 */
			usb_dm_pa11: usb_dm_pa11 {
				pinmux = < 0x16e >; /* in modules/hal/stm32/dts/st/f3/stm32f302v(b-c)tx-pinctrl.dtsi:1751 */
				phandle = < 0x15 >; /* in zephyr/boards/seco/stm32f3_seco_d23/stm32f3_seco_d23.dts:168 */
			};

			/* node '/soc/pin-controller@48000000/usb_dp_pa12' defined in modules/hal/stm32/dts/st/f3/stm32f302v(b-c)tx-pinctrl.dtsi:1754 */
			usb_dp_pa12: usb_dp_pa12 {
				pinmux = < 0x18e >; /* in modules/hal/stm32/dts/st/f3/stm32f302v(b-c)tx-pinctrl.dtsi:1755 */
				phandle = < 0x16 >; /* in zephyr/boards/seco/stm32f3_seco_d23/stm32f3_seco_d23.dts:168 */
			};
		};

		/* node '/soc/watchdog@40003000' defined in zephyr/dts/arm/st/f3/stm32f3.dtsi:173 */
		iwdg: watchdog@40003000 {
			compatible = "st,stm32-watchdog"; /* in zephyr/dts/arm/st/f3/stm32f3.dtsi:174 */
			reg = < 0x40003000 0x400 >;       /* in zephyr/dts/arm/st/f3/stm32f3.dtsi:175 */
			status = "okay";                  /* in zephyr/boards/seco/stm32f3_seco_d23/stm32f3_seco_d23.dts:226 */
		};

		/* node '/soc/watchdog@40002c00' defined in zephyr/dts/arm/st/f3/stm32f3.dtsi:179 */
		wwdg: watchdog@40002c00 {
			compatible = "st,stm32-window-watchdog"; /* in zephyr/dts/arm/st/f3/stm32f3.dtsi:180 */
			reg = < 0x40002c00 0x400 >;              /* in zephyr/dts/arm/st/f3/stm32f3.dtsi:181 */
			clocks = < &rcc 0x1c 0x800 >;            /* in zephyr/dts/arm/st/f3/stm32f3.dtsi:182 */
			interrupts = < 0x0 0x7 >;                /* in zephyr/dts/arm/st/f3/stm32f3.dtsi:183 */
			status = "disabled";                     /* in zephyr/dts/arm/st/f3/stm32f3.dtsi:184 */
		};

		/* node '/soc/serial@40013800' defined in zephyr/dts/arm/st/f3/stm32f3.dtsi:187 */
		usart1: serial@40013800 {
			compatible = "st,stm32-usart",
			             "st,stm32-uart";                   /* in zephyr/dts/arm/st/f3/stm32f3.dtsi:188 */
			reg = < 0x40013800 0x400 >;                     /* in zephyr/dts/arm/st/f3/stm32f3.dtsi:189 */
			clocks = < &rcc 0x18 0x4000 >;                  /* in zephyr/dts/arm/st/f3/stm32f3.dtsi:190 */
			resets = < &rctl 0x18e >;                       /* in zephyr/dts/arm/st/f3/stm32f3.dtsi:191 */
			interrupts = < 0x25 0x0 >;                      /* in zephyr/dts/arm/st/f3/stm32f3.dtsi:192 */
			pinctrl-0 = < &usart1_tx_pa9 &usart1_rx_pa10 >; /* in zephyr/boards/seco/stm32f3_seco_d23/stm32f3_seco_d23.dts:111 */
			pinctrl-names = "default";                      /* in zephyr/boards/seco/stm32f3_seco_d23/stm32f3_seco_d23.dts:112 */
			current-speed = < 0x1c200 >;                    /* in zephyr/boards/seco/stm32f3_seco_d23/stm32f3_seco_d23.dts:113 */
			status = "okay";                                /* in zephyr/boards/seco/stm32f3_seco_d23/stm32f3_seco_d23.dts:114 */
		};

		/* node '/soc/serial@40004400' defined in zephyr/dts/arm/st/f3/stm32f3.dtsi:196 */
		usart2: serial@40004400 {
			compatible = "st,stm32-usart",
			             "st,stm32-uart";                                                  /* in zephyr/dts/arm/st/f3/stm32f3.dtsi:197 */
			reg = < 0x40004400 0x400 >;                                                    /* in zephyr/dts/arm/st/f3/stm32f3.dtsi:198 */
			clocks = < &rcc 0x1c 0x20000 >;                                                /* in zephyr/dts/arm/st/f3/stm32f3.dtsi:199 */
			resets = < &rctl 0x211 >;                                                      /* in zephyr/dts/arm/st/f3/stm32f3.dtsi:200 */
			interrupts = < 0x26 0x0 >;                                                     /* in zephyr/dts/arm/st/f3/stm32f3.dtsi:201 */
			status = "disabled";                                                           /* in zephyr/dts/arm/st/f3/stm32f3.dtsi:202 */
			pinctrl-0 = < &usart2_tx_pd5 &usart2_rx_pd6 &usart2_cts_pd3 &usart2_rts_pd4 >; /* in zephyr/boards/seco/stm32f3_seco_d23/stm32f3_seco_d23.dts:119 */
			pinctrl-names = "default";                                                     /* in zephyr/boards/seco/stm32f3_seco_d23/stm32f3_seco_d23.dts:121 */
			current-speed = < 0x1c200 >;                                                   /* in zephyr/boards/seco/stm32f3_seco_d23/stm32f3_seco_d23.dts:122 */
		};

		/* node '/soc/serial@40004800' defined in zephyr/dts/arm/st/f3/stm32f3.dtsi:205 */
		usart3: serial@40004800 {
			compatible = "st,stm32-usart",
			             "st,stm32-uart";                                     /* in zephyr/dts/arm/st/f3/stm32f3.dtsi:206 */
			reg = < 0x40004800 0x400 >;                                       /* in zephyr/dts/arm/st/f3/stm32f3.dtsi:207 */
			clocks = < &rcc 0x1c 0x40000 >;                                   /* in zephyr/dts/arm/st/f3/stm32f3.dtsi:208 */
			resets = < &rctl 0x212 >;                                         /* in zephyr/dts/arm/st/f3/stm32f3.dtsi:209 */
			interrupts = < 0x27 0x0 >;                                        /* in zephyr/dts/arm/st/f3/stm32f3.dtsi:210 */
			status = "disabled";                                              /* in zephyr/dts/arm/st/f3/stm32f3.dtsi:211 */
			pinctrl-0 = < &usart3_tx_pc10 &usart3_rx_pc11 &usart3_rts_pd12 >; /* in zephyr/boards/seco/stm32f3_seco_d23/stm32f3_seco_d23.dts:127 */
			pinctrl-names = "default";                                        /* in zephyr/boards/seco/stm32f3_seco_d23/stm32f3_seco_d23.dts:129 */
			current-speed = < 0x1c200 >;                                      /* in zephyr/boards/seco/stm32f3_seco_d23/stm32f3_seco_d23.dts:130 */
		};

		/* node '/soc/serial@40004c00' defined in zephyr/dts/arm/st/f3/stm32f3.dtsi:214 */
		uart4: serial@40004c00 {
			compatible = "st,stm32-uart";   /* in zephyr/dts/arm/st/f3/stm32f3.dtsi:215 */
			reg = < 0x40004c00 0x400 >;     /* in zephyr/dts/arm/st/f3/stm32f3.dtsi:216 */
			clocks = < &rcc 0x1c 0x80000 >; /* in zephyr/dts/arm/st/f3/stm32f3.dtsi:217 */
			resets = < &rctl 0x213 >;       /* in zephyr/dts/arm/st/f3/stm32f3.dtsi:218 */
			interrupts = < 0x34 0x0 >;      /* in zephyr/dts/arm/st/f3/stm32f3.dtsi:219 */
			status = "disabled";            /* in zephyr/dts/arm/st/f3/stm32f3.dtsi:220 */
		};

		/* node '/soc/i2c@40005400' defined in zephyr/dts/arm/st/f3/stm32f3.dtsi:223 */
		i2c1: i2c@40005400 {
			compatible = "st,stm32-i2c-v2";              /* in zephyr/dts/arm/st/f3/stm32f3.dtsi:224 */
			#address-cells = < 0x1 >;                    /* in zephyr/dts/arm/st/f3/stm32f3.dtsi:226 */
			#size-cells = < 0x0 >;                       /* in zephyr/dts/arm/st/f3/stm32f3.dtsi:227 */
			reg = < 0x40005400 0x400 >;                  /* in zephyr/dts/arm/st/f3/stm32f3.dtsi:228 */
			clocks = < &rcc 0x1c 0x200000 >,
			         < &rcc 0x1 0x1040030 >;             /* in zephyr/dts/arm/st/f3/stm32f3.dtsi:229 */
			interrupts = < 0x1f 0x0 >,
			             < 0x20 0x0 >;                   /* in zephyr/dts/arm/st/f3/stm32f3.dtsi:234 */
			interrupt-names = "event",
			                  "error";                   /* in zephyr/dts/arm/st/f3/stm32f3.dtsi:235 */
			pinctrl-0 = < &i2c1_scl_pb6 &i2c1_sda_pb7 >; /* in zephyr/boards/seco/stm32f3_seco_d23/stm32f3_seco_d23.dts:140 */
			pinctrl-names = "default";                   /* in zephyr/boards/seco/stm32f3_seco_d23/stm32f3_seco_d23.dts:141 */
			clock-frequency = < 0x61a80 >;               /* in zephyr/boards/seco/stm32f3_seco_d23/stm32f3_seco_d23.dts:142 */
			status = "okay";                             /* in zephyr/boards/seco/stm32f3_seco_d23/stm32f3_seco_d23.dts:143 */
			phandle = < 0x2d >;                          /* in zephyr/dts/arm/st/f3/stm32f3.dtsi:450 */
		};

		/* node '/soc/spi@40013000' defined in zephyr/dts/arm/st/f3/stm32f3.dtsi:239 */
		spi1: spi@40013000 {
			compatible = "st,stm32-spi-fifo",
			             "st,stm32-spi";                                               /* in zephyr/dts/arm/st/f3/stm32f3.dtsi:240 */
			#address-cells = < 0x1 >;                                                  /* in zephyr/dts/arm/st/f3/stm32f3.dtsi:241 */
			#size-cells = < 0x0 >;                                                     /* in zephyr/dts/arm/st/f3/stm32f3.dtsi:242 */
			reg = < 0x40013000 0x400 >;                                                /* in zephyr/dts/arm/st/f3/stm32f3.dtsi:243 */
			clocks = < &rcc 0x18 0x1000 >;                                             /* in zephyr/dts/arm/st/f3/stm32f3.dtsi:244 */
			interrupts = < 0x23 0x5 >;                                                 /* in zephyr/dts/arm/st/f3/stm32f3.dtsi:245 */
			pinctrl-0 = < &spi1_nss_pa4 &spi1_sck_pb3 &spi1_miso_pb4 &spi1_mosi_pb5 >; /* in zephyr/boards/seco/stm32f3_seco_d23/stm32f3_seco_d23.dts:154 */
			pinctrl-names = "default";                                                 /* in zephyr/boards/seco/stm32f3_seco_d23/stm32f3_seco_d23.dts:156 */
			status = "okay";                                                           /* in zephyr/boards/seco/stm32f3_seco_d23/stm32f3_seco_d23.dts:157 */
		};

		/* node '/soc/dac@40007400' defined in zephyr/dts/arm/st/f3/stm32f3.dtsi:249 */
		dac1: dac@40007400 {
			compatible = "st,stm32-dac";       /* in zephyr/dts/arm/st/f3/stm32f3.dtsi:250 */
			reg = < 0x40007400 0x400 >;        /* in zephyr/dts/arm/st/f3/stm32f3.dtsi:251 */
			clocks = < &rcc 0x1c 0x20000000 >; /* in zephyr/dts/arm/st/f3/stm32f3.dtsi:252 */
			status = "disabled";               /* in zephyr/dts/arm/st/f3/stm32f3.dtsi:253 */
			#io-channel-cells = < 0x1 >;       /* in zephyr/dts/arm/st/f3/stm32f3.dtsi:254 */
		};

		/* node '/soc/usb@40005c00' defined in zephyr/dts/arm/st/f3/stm32f3.dtsi:257 */
		usb: zephyr_udc0: usb@40005c00 {
			compatible = "st,stm32-usb";               /* in zephyr/dts/arm/st/f3/stm32f3.dtsi:258 */
			reg = < 0x40005c00 0x400 >;                /* in zephyr/dts/arm/st/f3/stm32f3.dtsi:259 */
			interrupt-names = "usb";                   /* in zephyr/dts/arm/st/f3/stm32f3.dtsi:261 */
			num-bidir-endpoints = < 0x8 >;             /* in zephyr/dts/arm/st/f3/stm32f3.dtsi:262 */
			ram-size = < 0x200 >;                      /* in zephyr/dts/arm/st/f3/stm32f3.dtsi:263 */
			maximum-speed = "full-speed";              /* in zephyr/dts/arm/st/f3/stm32f3.dtsi:264 */
			phys = < &usb_fs_phy >;                    /* in zephyr/dts/arm/st/f3/stm32f3.dtsi:265 */
			clocks = < &rcc 0x1c 0x800000 >;           /* in zephyr/dts/arm/st/f3/stm32f3.dtsi:266 */
			interrupts = < 0x4b 0x0 >;                 /* in zephyr/dts/arm/st/f3/stm32f302.dtsi:16 */
			pinctrl-0 = < &usb_dm_pa11 &usb_dp_pa12 >; /* in zephyr/boards/seco/stm32f3_seco_d23/stm32f3_seco_d23.dts:168 */
			pinctrl-names = "default";                 /* in zephyr/boards/seco/stm32f3_seco_d23/stm32f3_seco_d23.dts:169 */
			status = "okay";                           /* in zephyr/boards/seco/stm32f3_seco_d23/stm32f3_seco_d23.dts:170 */
		};

		/* node '/soc/timers@40000000' defined in zephyr/dts/arm/st/f3/stm32f3.dtsi:270 */
		timers2: timers@40000000 {
			compatible = "st,stm32-timers"; /* in zephyr/dts/arm/st/f3/stm32f3.dtsi:271 */
			reg = < 0x40000000 0x400 >;     /* in zephyr/dts/arm/st/f3/stm32f3.dtsi:272 */
			resets = < &rctl 0x200 >;       /* in zephyr/dts/arm/st/f3/stm32f3.dtsi:275 */
			interrupts = < 0x1c 0x0 >;      /* in zephyr/dts/arm/st/f3/stm32f3.dtsi:276 */
			interrupt-names = "global";     /* in zephyr/dts/arm/st/f3/stm32f3.dtsi:277 */
			st,prescaler = < 0x0 >;         /* in zephyr/dts/arm/st/f3/stm32f3.dtsi:278 */
			status = "disabled";            /* in zephyr/dts/arm/st/f3/stm32f3.dtsi:279 */
			clocks = < &rcc 0x1c 0x1 >,
			         < &rcc 0x6 0x180030 >; /* in zephyr/dts/arm/st/f3/stm32f302Xc.dtsi:23 */

			/* node '/soc/timers@40000000/pwm' defined in zephyr/dts/arm/st/f3/stm32f3.dtsi:281 */
			pwm {
				compatible = "st,stm32-pwm"; /* in zephyr/dts/arm/st/f3/stm32f3.dtsi:282 */
				status = "disabled";         /* in zephyr/dts/arm/st/f3/stm32f3.dtsi:283 */
				#pwm-cells = < 0x3 >;        /* in zephyr/dts/arm/st/f3/stm32f3.dtsi:284 */
			};

			/* node '/soc/timers@40000000/counter' defined in zephyr/dts/arm/st/f3/stm32f3.dtsi:287 */
			counter {
				compatible = "st,stm32-counter"; /* in zephyr/dts/arm/st/f3/stm32f3.dtsi:288 */
				status = "disabled";             /* in zephyr/dts/arm/st/f3/stm32f3.dtsi:289 */
			};

			/* node '/soc/timers@40000000/qdec' defined in zephyr/dts/arm/st/f3/stm32f3.dtsi:292 */
			qdec {
				compatible = "st,stm32-qdec";    /* in zephyr/dts/arm/st/f3/stm32f3.dtsi:293 */
				st,input-filter-level = < 0x0 >; /* in zephyr/dts/arm/st/f3/stm32f3.dtsi:294 */
				status = "disabled";             /* in zephyr/dts/arm/st/f3/stm32f3.dtsi:295 */
			};
		};

		/* node '/soc/timers@40001000' defined in zephyr/dts/arm/st/f3/stm32f3.dtsi:299 */
		timers6: timers@40001000 {
			compatible = "st,stm32-timers"; /* in zephyr/dts/arm/st/f3/stm32f3.dtsi:300 */
			reg = < 0x40001000 0x400 >;     /* in zephyr/dts/arm/st/f3/stm32f3.dtsi:301 */
			clocks = < &rcc 0x1c 0x10 >,
			         < &rcc 0x6 0xff >;     /* in zephyr/dts/arm/st/f3/stm32f3.dtsi:302 */
			resets = < &rctl 0x204 >;       /* in zephyr/dts/arm/st/f3/stm32f3.dtsi:304 */
			interrupts = < 0x36 0x0 >;      /* in zephyr/dts/arm/st/f3/stm32f3.dtsi:305 */
			interrupt-names = "global";     /* in zephyr/dts/arm/st/f3/stm32f3.dtsi:306 */
			st,prescaler = < 0x0 >;         /* in zephyr/dts/arm/st/f3/stm32f3.dtsi:307 */
			status = "disabled";            /* in zephyr/dts/arm/st/f3/stm32f3.dtsi:308 */

			/* node '/soc/timers@40001000/counter' defined in zephyr/dts/arm/st/f3/stm32f3.dtsi:310 */
			counter {
				compatible = "st,stm32-counter"; /* in zephyr/dts/arm/st/f3/stm32f3.dtsi:311 */
				status = "disabled";             /* in zephyr/dts/arm/st/f3/stm32f3.dtsi:312 */
			};
		};

		/* node '/soc/timers@40014000' defined in zephyr/dts/arm/st/f3/stm32f3.dtsi:316 */
		timers15: timers@40014000 {
			compatible = "st,stm32-timers"; /* in zephyr/dts/arm/st/f3/stm32f3.dtsi:317 */
			reg = < 0x40014000 0x400 >;     /* in zephyr/dts/arm/st/f3/stm32f3.dtsi:318 */
			resets = < &rctl 0x190 >;       /* in zephyr/dts/arm/st/f3/stm32f3.dtsi:321 */
			interrupts = < 0x18 0x0 >;      /* in zephyr/dts/arm/st/f3/stm32f3.dtsi:322 */
			interrupt-names = "global";     /* in zephyr/dts/arm/st/f3/stm32f3.dtsi:323 */
			st,prescaler = < 0x0 >;         /* in zephyr/dts/arm/st/f3/stm32f3.dtsi:324 */
			status = "disabled";            /* in zephyr/dts/arm/st/f3/stm32f3.dtsi:325 */
			clocks = < &rcc 0x18 0x10000 >,
			         < &rcc 0x7 0xa0030 >;  /* in zephyr/dts/arm/st/f3/stm32f302.dtsi:96 */

			/* node '/soc/timers@40014000/pwm' defined in zephyr/dts/arm/st/f3/stm32f3.dtsi:327 */
			pwm {
				compatible = "st,stm32-pwm"; /* in zephyr/dts/arm/st/f3/stm32f3.dtsi:328 */
				status = "disabled";         /* in zephyr/dts/arm/st/f3/stm32f3.dtsi:329 */
				#pwm-cells = < 0x3 >;        /* in zephyr/dts/arm/st/f3/stm32f3.dtsi:330 */
			};

			/* node '/soc/timers@40014000/counter' defined in zephyr/dts/arm/st/f3/stm32f3.dtsi:333 */
			counter {
				compatible = "st,stm32-counter"; /* in zephyr/dts/arm/st/f3/stm32f3.dtsi:334 */
				status = "disabled";             /* in zephyr/dts/arm/st/f3/stm32f3.dtsi:335 */
			};
		};

		/* node '/soc/timers@40014400' defined in zephyr/dts/arm/st/f3/stm32f3.dtsi:339 */
		timers16: timers@40014400 {
			compatible = "st,stm32-timers"; /* in zephyr/dts/arm/st/f3/stm32f3.dtsi:340 */
			reg = < 0x40014400 0x400 >;     /* in zephyr/dts/arm/st/f3/stm32f3.dtsi:341 */
			resets = < &rctl 0x191 >;       /* in zephyr/dts/arm/st/f3/stm32f3.dtsi:344 */
			interrupts = < 0x19 0x0 >;      /* in zephyr/dts/arm/st/f3/stm32f3.dtsi:345 */
			interrupt-names = "global";     /* in zephyr/dts/arm/st/f3/stm32f3.dtsi:346 */
			st,prescaler = < 0x0 >;         /* in zephyr/dts/arm/st/f3/stm32f3.dtsi:347 */
			status = "disabled";            /* in zephyr/dts/arm/st/f3/stm32f3.dtsi:348 */
			clocks = < &rcc 0x18 0x20000 >,
			         < &rcc 0x7 0xb0030 >;  /* in zephyr/dts/arm/st/f3/stm32f302.dtsi:101 */

			/* node '/soc/timers@40014400/pwm' defined in zephyr/dts/arm/st/f3/stm32f3.dtsi:350 */
			pwm {
				compatible = "st,stm32-pwm"; /* in zephyr/dts/arm/st/f3/stm32f3.dtsi:351 */
				status = "disabled";         /* in zephyr/dts/arm/st/f3/stm32f3.dtsi:352 */
				#pwm-cells = < 0x3 >;        /* in zephyr/dts/arm/st/f3/stm32f3.dtsi:353 */
			};

			/* node '/soc/timers@40014400/counter' defined in zephyr/dts/arm/st/f3/stm32f3.dtsi:356 */
			counter {
				compatible = "st,stm32-counter"; /* in zephyr/dts/arm/st/f3/stm32f3.dtsi:357 */
				status = "disabled";             /* in zephyr/dts/arm/st/f3/stm32f3.dtsi:358 */
			};
		};

		/* node '/soc/timers@40014800' defined in zephyr/dts/arm/st/f3/stm32f3.dtsi:362 */
		timers17: timers@40014800 {
			compatible = "st,stm32-timers"; /* in zephyr/dts/arm/st/f3/stm32f3.dtsi:363 */
			reg = < 0x40014800 0x400 >;     /* in zephyr/dts/arm/st/f3/stm32f3.dtsi:364 */
			resets = < &rctl 0x192 >;       /* in zephyr/dts/arm/st/f3/stm32f3.dtsi:367 */
			interrupts = < 0x1a 0x0 >;      /* in zephyr/dts/arm/st/f3/stm32f3.dtsi:368 */
			interrupt-names = "global";     /* in zephyr/dts/arm/st/f3/stm32f3.dtsi:369 */
			st,prescaler = < 0x0 >;         /* in zephyr/dts/arm/st/f3/stm32f3.dtsi:370 */
			status = "disabled";            /* in zephyr/dts/arm/st/f3/stm32f3.dtsi:371 */
			clocks = < &rcc 0x18 0x40000 >,
			         < &rcc 0x7 0xd0030 >;  /* in zephyr/dts/arm/st/f3/stm32f302.dtsi:106 */

			/* node '/soc/timers@40014800/pwm' defined in zephyr/dts/arm/st/f3/stm32f3.dtsi:373 */
			pwm {
				compatible = "st,stm32-pwm"; /* in zephyr/dts/arm/st/f3/stm32f3.dtsi:374 */
				status = "disabled";         /* in zephyr/dts/arm/st/f3/stm32f3.dtsi:375 */
				#pwm-cells = < 0x3 >;        /* in zephyr/dts/arm/st/f3/stm32f3.dtsi:376 */
			};

			/* node '/soc/timers@40014800/counter' defined in zephyr/dts/arm/st/f3/stm32f3.dtsi:379 */
			counter {
				compatible = "st,stm32-counter"; /* in zephyr/dts/arm/st/f3/stm32f3.dtsi:380 */
				status = "disabled";             /* in zephyr/dts/arm/st/f3/stm32f3.dtsi:381 */
			};
		};

		/* node '/soc/rtc@40002800' defined in zephyr/dts/arm/st/f3/stm32f3.dtsi:385 */
		rtc: rtc@40002800 {
			compatible = "st,stm32-rtc";       /* in zephyr/dts/arm/st/f3/stm32f3.dtsi:386 */
			reg = < 0x40002800 0x400 >;        /* in zephyr/dts/arm/st/f3/stm32f3.dtsi:387 */
			interrupts = < 0x29 0x0 >;         /* in zephyr/dts/arm/st/f3/stm32f3.dtsi:389 */
			prescaler = < 0x8000 >;            /* in zephyr/dts/arm/st/f3/stm32f3.dtsi:390 */
			alarms-count = < 0x2 >;            /* in zephyr/dts/arm/st/f3/stm32f3.dtsi:391 */
			alrm-exti-line = < 0x11 >;         /* in zephyr/dts/arm/st/f3/stm32f3.dtsi:392 */
			clocks = < &rcc 0x1c 0x10000000 >,
			         < &rcc 0x3 0x2280020 >;   /* in zephyr/boards/seco/stm32f3_seco_d23/stm32f3_seco_d23.dts:174 */
			status = "okay";                   /* in zephyr/boards/seco/stm32f3_seco_d23/stm32f3_seco_d23.dts:176 */
		};

		/* node '/soc/can@40006400' defined in zephyr/dts/arm/st/f3/stm32f3.dtsi:396 */
		can1: can@40006400 {
			compatible = "st,stm32-bxcan";           /* in zephyr/dts/arm/st/f3/stm32f3.dtsi:397 */
			reg = < 0x40006400 0x400 >;              /* in zephyr/dts/arm/st/f3/stm32f3.dtsi:398 */
			interrupts = < 0x13 0x0 >,
			             < 0x14 0x0 >,
			             < 0x15 0x0 >,
			             < 0x16 0x0 >;               /* in zephyr/dts/arm/st/f3/stm32f3.dtsi:399 */
			interrupt-names = "TX",
			                  "RX0",
			                  "RX1",
			                  "SCE";                 /* in zephyr/dts/arm/st/f3/stm32f3.dtsi:400 */
			clocks = < &rcc 0x1c 0x2000000 >;        /* in zephyr/dts/arm/st/f3/stm32f3.dtsi:401 */
			pinctrl-0 = < &can_rx_pb8 &can_tx_pb9 >; /* in zephyr/boards/seco/stm32f3_seco_d23/stm32f3_seco_d23.dts:180 */
			pinctrl-names = "default";               /* in zephyr/boards/seco/stm32f3_seco_d23/stm32f3_seco_d23.dts:181 */
			phys = < &transceiver0 >;                /* in zephyr/boards/seco/stm32f3_seco_d23/stm32f3_seco_d23.dts:182 */
			status = "okay";                         /* in zephyr/boards/seco/stm32f3_seco_d23/stm32f3_seco_d23.dts:183 */
		};

		/* node '/soc/dma@40020000' defined in zephyr/dts/arm/st/f3/stm32f3.dtsi:405 */
		dma1: dma@40020000 {
			compatible = "st,stm32-dma-v2bis";                                          /* in zephyr/dts/arm/st/f3/stm32f3.dtsi:406 */
			#dma-cells = < 0x2 >;                                                       /* in zephyr/dts/arm/st/f3/stm32f3.dtsi:407 */
			reg = < 0x40020000 0x400 >;                                                 /* in zephyr/dts/arm/st/f3/stm32f3.dtsi:408 */
			clocks = < &rcc 0x14 0x1 >;                                                 /* in zephyr/dts/arm/st/f3/stm32f3.dtsi:409 */
			interrupts = < 0xb 0x0 0xc 0x0 0xd 0x0 0xe 0x0 0xf 0x0 0x10 0x0 0x11 0x0 >; /* in zephyr/dts/arm/st/f3/stm32f3.dtsi:410 */
			status = "disabled";                                                        /* in zephyr/dts/arm/st/f3/stm32f3.dtsi:411 */
		};

		/* node '/soc/i2c@40005800' defined in zephyr/dts/arm/st/f3/stm32f302.dtsi:19 */
		i2c2: i2c@40005800 {
			compatible = "st,stm32-i2c-v2";               /* in zephyr/dts/arm/st/f3/stm32f302.dtsi:20 */
			#address-cells = < 0x1 >;                     /* in zephyr/dts/arm/st/f3/stm32f302.dtsi:22 */
			#size-cells = < 0x0 >;                        /* in zephyr/dts/arm/st/f3/stm32f302.dtsi:23 */
			reg = < 0x40005800 0x400 >;                   /* in zephyr/dts/arm/st/f3/stm32f302.dtsi:24 */
			clocks = < &rcc 0x1c 0x400000 >,
			         < &rcc 0x1 0x1050030 >;              /* in zephyr/dts/arm/st/f3/stm32f302.dtsi:25 */
			interrupts = < 0x21 0x0 >,
			             < 0x22 0x0 >;                    /* in zephyr/dts/arm/st/f3/stm32f302.dtsi:30 */
			interrupt-names = "event",
			                  "error";                    /* in zephyr/dts/arm/st/f3/stm32f302.dtsi:31 */
			status = "disabled";                          /* in zephyr/dts/arm/st/f3/stm32f302.dtsi:32 */
			pinctrl-0 = < &i2c2_scl_pa9 &i2c2_sda_pa10 >; /* in zephyr/boards/seco/stm32f3_seco_d23/stm32f3_seco_d23.dts:148 */
			pinctrl-names = "default";                    /* in zephyr/boards/seco/stm32f3_seco_d23/stm32f3_seco_d23.dts:149 */
			clock-frequency = < 0x61a80 >;                /* in zephyr/boards/seco/stm32f3_seco_d23/stm32f3_seco_d23.dts:150 */
			phandle = < 0x2e >;                           /* in zephyr/dts/arm/st/f3/stm32f302.dtsi:134 */
		};

		/* node '/soc/spi@40003800' defined in zephyr/dts/arm/st/f3/stm32f302.dtsi:51 */
		spi2: spi@40003800 {
			compatible = "st,stm32-spi-fifo",
			             "st,stm32-spi";                                                   /* in zephyr/dts/arm/st/f3/stm32f302.dtsi:52 */
			#address-cells = < 0x1 >;                                                      /* in zephyr/dts/arm/st/f3/stm32f302.dtsi:53 */
			#size-cells = < 0x0 >;                                                         /* in zephyr/dts/arm/st/f3/stm32f302.dtsi:54 */
			reg = < 0x40003800 0x400 >;                                                    /* in zephyr/dts/arm/st/f3/stm32f302.dtsi:55 */
			clocks = < &rcc 0x1c 0x4000 >;                                                 /* in zephyr/dts/arm/st/f3/stm32f302.dtsi:56 */
			interrupts = < 0x24 0x5 >;                                                     /* in zephyr/dts/arm/st/f3/stm32f302.dtsi:57 */
			pinctrl-0 = < &spi2_nss_pb12 &spi2_sck_pb13 &spi2_miso_pb14 &spi2_mosi_pb15 >; /* in zephyr/boards/seco/stm32f3_seco_d23/stm32f3_seco_d23.dts:161 */
			pinctrl-names = "default";                                                     /* in zephyr/boards/seco/stm32f3_seco_d23/stm32f3_seco_d23.dts:163 */
			status = "okay";                                                               /* in zephyr/boards/seco/stm32f3_seco_d23/stm32f3_seco_d23.dts:164 */
		};

		/* node '/soc/spi@40003c00' defined in zephyr/dts/arm/st/f3/stm32f302.dtsi:61 */
		spi3: spi@40003c00 {
			compatible = "st,stm32-spi-fifo",
			             "st,stm32-spi";      /* in zephyr/dts/arm/st/f3/stm32f302.dtsi:62 */
			#address-cells = < 0x1 >;         /* in zephyr/dts/arm/st/f3/stm32f302.dtsi:63 */
			#size-cells = < 0x0 >;            /* in zephyr/dts/arm/st/f3/stm32f302.dtsi:64 */
			reg = < 0x40003c00 0x400 >;       /* in zephyr/dts/arm/st/f3/stm32f302.dtsi:65 */
			clocks = < &rcc 0x1c 0x8000 >;    /* in zephyr/dts/arm/st/f3/stm32f302.dtsi:66 */
			interrupts = < 0x33 0x5 >;        /* in zephyr/dts/arm/st/f3/stm32f302.dtsi:67 */
			status = "disabled";              /* in zephyr/dts/arm/st/f3/stm32f302.dtsi:68 */
		};

		/* node '/soc/timers@40012c00' defined in zephyr/dts/arm/st/f3/stm32f302.dtsi:71 */
		timers1: timers@40012c00 {
			compatible = "st,stm32-timers"; /* in zephyr/dts/arm/st/f3/stm32f302.dtsi:72 */
			reg = < 0x40012c00 0x400 >;     /* in zephyr/dts/arm/st/f3/stm32f302.dtsi:73 */
			clocks = < &rcc 0x18 0x800 >,
			         < &rcc 0x7 0x80030 >;  /* in zephyr/dts/arm/st/f3/stm32f302.dtsi:74 */
			resets = < &rctl 0x18b >;       /* in zephyr/dts/arm/st/f3/stm32f302.dtsi:76 */
			interrupts = < 0x18 0x0 >,
			             < 0x19 0x0 >,
			             < 0x1a 0x0 >,
			             < 0x1b 0x0 >;      /* in zephyr/dts/arm/st/f3/stm32f302.dtsi:77 */
			interrupt-names = "brk",
			                  "up",
			                  "trgcom",
			                  "cc";         /* in zephyr/dts/arm/st/f3/stm32f302.dtsi:78 */
			st,prescaler = < 0x2710 >;      /* in zephyr/boards/seco/stm32f3_seco_d23/stm32f3_seco_d23.dts:230 */
			status = "okay";                /* in zephyr/boards/seco/stm32f3_seco_d23/stm32f3_seco_d23.dts:231 */

			/* node '/soc/timers@40012c00/pwm' defined in zephyr/dts/arm/st/f3/stm32f302.dtsi:82 */
			pwm1: pwm {
				compatible = "st,stm32-pwm";                                                                                /* in zephyr/dts/arm/st/f3/stm32f302.dtsi:83 */
				#pwm-cells = < 0x3 >;                                                                                       /* in zephyr/dts/arm/st/f3/stm32f302.dtsi:85 */
				pinctrl-0 = < &tim1_ch1_pe9 &tim1_ch2n_pe10 &tim1_ch2_pe11 &tim1_ch3n_pe12 &tim1_ch3_pe13 &tim1_ch4_pe14 >; /* in zephyr/boards/seco/stm32f3_seco_d23/stm32f3_seco_d23.dts:234 */
				pinctrl-names = "default";                                                                                  /* in zephyr/boards/seco/stm32f3_seco_d23/stm32f3_seco_d23.dts:236 */
				status = "okay";                                                                                            /* in zephyr/boards/seco/stm32f3_seco_d23/stm32f3_seco_d23.dts:237 */
			};

			/* node '/soc/timers@40012c00/qdec' defined in zephyr/dts/arm/st/f3/stm32f302.dtsi:88 */
			qdec {
				compatible = "st,stm32-qdec";    /* in zephyr/dts/arm/st/f3/stm32f302.dtsi:89 */
				st,input-filter-level = < 0x0 >; /* in zephyr/dts/arm/st/f3/stm32f302.dtsi:90 */
				status = "disabled";             /* in zephyr/dts/arm/st/f3/stm32f302.dtsi:91 */
			};
		};

		/* node '/soc/adc@50000000' defined in zephyr/dts/arm/st/f3/stm32f302.dtsi:110 */
		adc1: adc@50000000 {
			compatible = "st,stm32-adc";                               /* in zephyr/dts/arm/st/f3/stm32f302.dtsi:111 */
			reg = < 0x50000000 0x400 >;                                /* in zephyr/dts/arm/st/f3/stm32f302.dtsi:112 */
			clocks = < &rcc 0x14 0x10000000 >;                         /* in zephyr/dts/arm/st/f3/stm32f302.dtsi:113 */
			clock-names = "adcx";                                      /* in zephyr/dts/arm/st/f3/stm32f302.dtsi:114 */
			interrupts = < 0x12 0x0 >;                                 /* in zephyr/dts/arm/st/f3/stm32f302.dtsi:115 */
			#io-channel-cells = < 0x1 >;                               /* in zephyr/dts/arm/st/f3/stm32f302.dtsi:116 */
			resolutions = < 0x60630c 0x51630c 0x42630c 0x33630c >;     /* in zephyr/dts/arm/st/f3/stm32f302.dtsi:117 */
			sampling-times = < 0x2 0x3 0x5 0x8 0x14 0x3e 0xb6 0x25a >; /* in zephyr/dts/arm/st/f3/stm32f302.dtsi:121 */
			st,adc-sequencer = "programmable";                         /* in zephyr/dts/arm/st/f3/stm32f302.dtsi:122 */
			st,adc-oversampler = "none";                               /* in zephyr/dts/arm/st/f3/stm32f302.dtsi:123 */
			st,adc-internal-regulator = "startup-sw-delay";            /* in zephyr/dts/arm/st/f3/stm32f302.dtsi:124 */
			st,adc-has-differential-support;                           /* in zephyr/dts/arm/st/f3/stm32f302.dtsi:125 */
			status = "disabled";                                       /* in zephyr/dts/arm/st/f3/stm32f302.dtsi:126 */
			phandle = < 0x2c >;                                        /* in zephyr/dts/arm/st/f3/stm32f3.dtsi:422 */
		};

		/* node '/soc/timers@40000400' defined in zephyr/dts/arm/st/f3/stm32f302Xc.dtsi:27 */
		timers3: timers@40000400 {
			compatible = "st,stm32-timers"; /* in zephyr/dts/arm/st/f3/stm32f302Xc.dtsi:28 */
			reg = < 0x40000400 0x400 >;     /* in zephyr/dts/arm/st/f3/stm32f302Xc.dtsi:29 */
			clocks = < &rcc 0x1c 0x2 >,
			         < &rcc 0x6 0x190030 >; /* in zephyr/dts/arm/st/f3/stm32f302Xc.dtsi:30 */
			resets = < &rctl 0x201 >;       /* in zephyr/dts/arm/st/f3/stm32f302Xc.dtsi:32 */
			interrupts = < 0x1d 0x0 >;      /* in zephyr/dts/arm/st/f3/stm32f302Xc.dtsi:33 */
			interrupt-names = "global";     /* in zephyr/dts/arm/st/f3/stm32f302Xc.dtsi:34 */
			st,prescaler = < 0x0 >;         /* in zephyr/dts/arm/st/f3/stm32f302Xc.dtsi:35 */
			status = "disabled";            /* in zephyr/dts/arm/st/f3/stm32f302Xc.dtsi:36 */

			/* node '/soc/timers@40000400/pwm' defined in zephyr/dts/arm/st/f3/stm32f302Xc.dtsi:38 */
			pwm {
				compatible = "st,stm32-pwm"; /* in zephyr/dts/arm/st/f3/stm32f302Xc.dtsi:39 */
				status = "disabled";         /* in zephyr/dts/arm/st/f3/stm32f302Xc.dtsi:40 */
				#pwm-cells = < 0x3 >;        /* in zephyr/dts/arm/st/f3/stm32f302Xc.dtsi:41 */
			};

			/* node '/soc/timers@40000400/counter' defined in zephyr/dts/arm/st/f3/stm32f302Xc.dtsi:44 */
			counter {
				compatible = "st,stm32-counter"; /* in zephyr/dts/arm/st/f3/stm32f302Xc.dtsi:45 */
				status = "disabled";             /* in zephyr/dts/arm/st/f3/stm32f302Xc.dtsi:46 */
			};

			/* node '/soc/timers@40000400/qdec' defined in zephyr/dts/arm/st/f3/stm32f302Xc.dtsi:49 */
			qdec {
				compatible = "st,stm32-qdec";    /* in zephyr/dts/arm/st/f3/stm32f302Xc.dtsi:50 */
				st,input-filter-level = < 0x0 >; /* in zephyr/dts/arm/st/f3/stm32f302Xc.dtsi:51 */
				status = "disabled";             /* in zephyr/dts/arm/st/f3/stm32f302Xc.dtsi:52 */
			};
		};

		/* node '/soc/timers@40000800' defined in zephyr/dts/arm/st/f3/stm32f302Xc.dtsi:56 */
		timers4: timers@40000800 {
			compatible = "st,stm32-timers"; /* in zephyr/dts/arm/st/f3/stm32f302Xc.dtsi:57 */
			reg = < 0x40000800 0x400 >;     /* in zephyr/dts/arm/st/f3/stm32f302Xc.dtsi:58 */
			clocks = < &rcc 0x1c 0x4 >,
			         < &rcc 0x6 0x190030 >; /* in zephyr/dts/arm/st/f3/stm32f302Xc.dtsi:59 */
			resets = < &rctl 0x202 >;       /* in zephyr/dts/arm/st/f3/stm32f302Xc.dtsi:61 */
			interrupts = < 0x1e 0x0 >;      /* in zephyr/dts/arm/st/f3/stm32f302Xc.dtsi:62 */
			interrupt-names = "global";     /* in zephyr/dts/arm/st/f3/stm32f302Xc.dtsi:63 */
			st,prescaler = < 0x2710 >;      /* in zephyr/boards/seco/stm32f3_seco_d23/stm32f3_seco_d23.dts:242 */
			status = "okay";                /* in zephyr/boards/seco/stm32f3_seco_d23/stm32f3_seco_d23.dts:243 */

			/* node '/soc/timers@40000800/pwm' defined in zephyr/dts/arm/st/f3/stm32f302Xc.dtsi:67 */
			pwm4: pwm {
				compatible = "st,stm32-pwm";                                  /* in zephyr/dts/arm/st/f3/stm32f302Xc.dtsi:68 */
				#pwm-cells = < 0x3 >;                                         /* in zephyr/dts/arm/st/f3/stm32f302Xc.dtsi:70 */
				pinctrl-0 = < &tim4_ch2_pd13 &tim4_ch3_pd14 &tim4_ch4_pd15 >; /* in zephyr/boards/seco/stm32f3_seco_d23/stm32f3_seco_d23.dts:246 */
				pinctrl-names = "default";                                    /* in zephyr/boards/seco/stm32f3_seco_d23/stm32f3_seco_d23.dts:247 */
				status = "okay";                                              /* in zephyr/boards/seco/stm32f3_seco_d23/stm32f3_seco_d23.dts:248 */
			};

			/* node '/soc/timers@40000800/qdec' defined in zephyr/dts/arm/st/f3/stm32f302Xc.dtsi:73 */
			qdec {
				compatible = "st,stm32-qdec";    /* in zephyr/dts/arm/st/f3/stm32f302Xc.dtsi:74 */
				st,input-filter-level = < 0x0 >; /* in zephyr/dts/arm/st/f3/stm32f302Xc.dtsi:75 */
				status = "disabled";             /* in zephyr/dts/arm/st/f3/stm32f302Xc.dtsi:76 */
			};
		};

		/* node '/soc/dma@40020400' defined in zephyr/dts/arm/st/f3/stm32f302Xc.dtsi:80 */
		dma2: dma@40020400 {
			compatible = "st,stm32-dma-v2bis";                             /* in zephyr/dts/arm/st/f3/stm32f302Xc.dtsi:81 */
			#dma-cells = < 0x2 >;                                          /* in zephyr/dts/arm/st/f3/stm32f302Xc.dtsi:82 */
			reg = < 0x40020400 0x400 >;                                    /* in zephyr/dts/arm/st/f3/stm32f302Xc.dtsi:83 */
			clocks = < &rcc 0x14 0x2 >;                                    /* in zephyr/dts/arm/st/f3/stm32f302Xc.dtsi:84 */
			interrupts = < 0x38 0x0 0x39 0x0 0x3a 0x0 0x3b 0x0 0x3c 0x0 >; /* in zephyr/dts/arm/st/f3/stm32f302Xc.dtsi:85 */
			status = "disabled";                                           /* in zephyr/dts/arm/st/f3/stm32f302Xc.dtsi:86 */
		};

		/* node '/soc/serial@40005000' defined in zephyr/dts/arm/st/f3/stm32f302Xc.dtsi:89 */
		uart5: serial@40005000 {
			compatible = "st,stm32-uart";                 /* in zephyr/dts/arm/st/f3/stm32f302Xc.dtsi:90 */
			reg = < 0x40005000 0x400 >;                   /* in zephyr/dts/arm/st/f3/stm32f302Xc.dtsi:91 */
			clocks = < &rcc 0x1c 0x100000 >;              /* in zephyr/dts/arm/st/f3/stm32f302Xc.dtsi:92 */
			interrupts = < 0x35 0x0 >;                    /* in zephyr/dts/arm/st/f3/stm32f302Xc.dtsi:93 */
			status = "disabled";                          /* in zephyr/dts/arm/st/f3/stm32f302Xc.dtsi:94 */
			pinctrl-0 = < &uart5_tx_pc12 &uart5_rx_pd2 >; /* in zephyr/boards/seco/stm32f3_seco_d23/stm32f3_seco_d23.dts:134 */
			pinctrl-names = "default";                    /* in zephyr/boards/seco/stm32f3_seco_d23/stm32f3_seco_d23.dts:135 */
			current-speed = < 0x1c200 >;                  /* in zephyr/boards/seco/stm32f3_seco_d23/stm32f3_seco_d23.dts:136 */
		};
	};

	/* node '/cpus' defined in zephyr/dts/arm/st/f3/stm32f3.dtsi:27 */
	cpus {
		#address-cells = < 0x1 >; /* in zephyr/dts/arm/st/f3/stm32f3.dtsi:28 */
		#size-cells = < 0x0 >;    /* in zephyr/dts/arm/st/f3/stm32f3.dtsi:29 */

		/* node '/cpus/cpu@0' defined in zephyr/dts/arm/st/f3/stm32f3.dtsi:31 */
		cpu0: cpu@0 {
			device_type = "cpu";           /* in zephyr/dts/arm/st/f3/stm32f3.dtsi:32 */
			compatible = "arm,cortex-m4f"; /* in zephyr/dts/arm/st/f3/stm32f3.dtsi:33 */
			reg = < 0x0 >;                 /* in zephyr/dts/arm/st/f3/stm32f3.dtsi:34 */
		};
	};

	/* node '/memory@20000000' defined in zephyr/dts/arm/st/f3/stm32f3.dtsi:38 */
	sram0: memory@20000000 {
		compatible = "zephyr,memory-region",
		             "mmio-sram";            /* in zephyr/dts/arm/st/f3/stm32f3.dtsi:39 */
		zephyr,memory-region = "SRAM0";      /* in zephyr/dts/arm/st/f3/stm32f3.dtsi:40 */
		reg = < 0x20000000 0xa000 >;         /* in zephyr/dts/arm/st/f3/stm32f302Xc.dtsi:12 */
	};

	/* node '/clocks' defined in zephyr/dts/arm/st/f3/stm32f3.dtsi:43 */
	clocks {

		/* node '/clocks/clk-hse' defined in zephyr/dts/arm/st/f3/stm32f3.dtsi:44 */
		clk_hse: clk-hse {
			#clock-cells = < 0x0 >;            /* in zephyr/dts/arm/st/f3/stm32f3.dtsi:45 */
			compatible = "st,stm32-hse-clock"; /* in zephyr/dts/arm/st/f3/stm32f3.dtsi:46 */
			clock-frequency = < 0x7a1200 >;    /* in zephyr/boards/seco/stm32f3_seco_d23/stm32f3_seco_d23.dts:89 */
			status = "okay";                   /* in zephyr/boards/seco/stm32f3_seco_d23/stm32f3_seco_d23.dts:90 */
			phandle = < 0x2b >;                /* in zephyr/boards/seco/stm32f3_seco_d23/stm32f3_seco_d23.dts:96 */
		};

		/* node '/clocks/clk-hsi' defined in zephyr/dts/arm/st/f3/stm32f3.dtsi:50 */
		clk_hsi: clk-hsi {
			#clock-cells = < 0x0 >;         /* in zephyr/dts/arm/st/f3/stm32f3.dtsi:51 */
			compatible = "fixed-clock";     /* in zephyr/dts/arm/st/f3/stm32f3.dtsi:52 */
			clock-frequency = < 0x7a1200 >; /* in zephyr/dts/arm/st/f3/stm32f3.dtsi:53 */
			status = "disabled";            /* in zephyr/dts/arm/st/f3/stm32f3.dtsi:54 */
		};

		/* node '/clocks/clk-lse' defined in zephyr/dts/arm/st/f3/stm32f3.dtsi:57 */
		clk_lse: clk-lse {
			#clock-cells = < 0x0 >;            /* in zephyr/dts/arm/st/f3/stm32f3.dtsi:58 */
			compatible = "st,stm32-lse-clock"; /* in zephyr/dts/arm/st/f3/stm32f3.dtsi:59 */
			clock-frequency = < 0x8000 >;      /* in zephyr/dts/arm/st/f3/stm32f3.dtsi:60 */
			driving-capability = < 0x0 >;      /* in zephyr/dts/arm/st/f3/stm32f3.dtsi:61 */
			status = "disabled";               /* in zephyr/dts/arm/st/f3/stm32f3.dtsi:62 */
		};

		/* node '/clocks/clk-lsi' defined in zephyr/dts/arm/st/f3/stm32f3.dtsi:65 */
		clk_lsi: clk-lsi {
			#clock-cells = < 0x0 >;       /* in zephyr/dts/arm/st/f3/stm32f3.dtsi:66 */
			compatible = "fixed-clock";   /* in zephyr/dts/arm/st/f3/stm32f3.dtsi:67 */
			clock-frequency = < 0x9c40 >; /* in zephyr/dts/arm/st/f3/stm32f3.dtsi:68 */
			status = "okay";              /* in zephyr/boards/seco/stm32f3_seco_d23/stm32f3_seco_d23.dts:85 */
		};

		/* node '/clocks/pll' defined in zephyr/dts/arm/st/f3/stm32f3.dtsi:72 */
		pll: pll {
			#clock-cells = < 0x0 >;              /* in zephyr/dts/arm/st/f3/stm32f3.dtsi:73 */
			compatible = "st,stm32f0-pll-clock"; /* in zephyr/dts/arm/st/f3/stm32f3.dtsi:74 */
			prediv = < 0x1 >;                    /* in zephyr/boards/seco/stm32f3_seco_d23/stm32f3_seco_d23.dts:94 */
			mul = < 0x9 >;                       /* in zephyr/boards/seco/stm32f3_seco_d23/stm32f3_seco_d23.dts:95 */
			clocks = < &clk_hse >;               /* in zephyr/boards/seco/stm32f3_seco_d23/stm32f3_seco_d23.dts:96 */
			status = "okay";                     /* in zephyr/boards/seco/stm32f3_seco_d23/stm32f3_seco_d23.dts:97 */
			phandle = < 0x3 >;                   /* in zephyr/boards/seco/stm32f3_seco_d23/stm32f3_seco_d23.dts:101 */
		};
	};

	/* node '/dietemp' defined in zephyr/dts/arm/st/f3/stm32f3.dtsi:415 */
	die_temp: dietemp {
		compatible = "st,stm32-temp-cal"; /* in zephyr/dts/arm/st/f3/stm32f3.dtsi:416 */
		ts-cal1-addr = < 0x1ffff7b8 >;    /* in zephyr/dts/arm/st/f3/stm32f3.dtsi:417 */
		ts-cal2-addr = < 0x1ffff7c2 >;    /* in zephyr/dts/arm/st/f3/stm32f3.dtsi:418 */
		ts-cal1-temp = < 0x1e >;          /* in zephyr/dts/arm/st/f3/stm32f3.dtsi:419 */
		ts-cal2-temp = < 0x6e >;          /* in zephyr/dts/arm/st/f3/stm32f3.dtsi:420 */
		ts-cal-vrefanalog = < 0xce4 >;    /* in zephyr/dts/arm/st/f3/stm32f3.dtsi:421 */
		io-channels = < &adc1 0x10 >;     /* in zephyr/dts/arm/st/f3/stm32f3.dtsi:422 */
		status = "disabled";              /* in zephyr/dts/arm/st/f3/stm32f3.dtsi:423 */
	};

	/* node '/vref' defined in zephyr/dts/arm/st/f3/stm32f3.dtsi:426 */
	vref: vref {
		compatible = "st,stm32-vref";      /* in zephyr/dts/arm/st/f3/stm32f3.dtsi:427 */
		vrefint-cal-addr = < 0x1ffff7ba >; /* in zephyr/dts/arm/st/f3/stm32f3.dtsi:428 */
		vrefint-cal-mv = < 0xce4 >;        /* in zephyr/dts/arm/st/f3/stm32f3.dtsi:429 */
		io-channels = < &adc1 0x12 >;      /* in zephyr/dts/arm/st/f3/stm32f3.dtsi:430 */
		status = "disabled";               /* in zephyr/dts/arm/st/f3/stm32f3.dtsi:431 */
	};

	/* node '/vbat' defined in zephyr/dts/arm/st/f3/stm32f3.dtsi:434 */
	vbat: vbat {
		compatible = "st,stm32-vbat"; /* in zephyr/dts/arm/st/f3/stm32f3.dtsi:435 */
		ratio = < 0x2 >;              /* in zephyr/dts/arm/st/f3/stm32f3.dtsi:436 */
		io-channels = < &adc1 0x11 >; /* in zephyr/dts/arm/st/f3/stm32f3.dtsi:437 */
		status = "disabled";          /* in zephyr/dts/arm/st/f3/stm32f3.dtsi:438 */
	};

	/* node '/usbphy' defined in zephyr/dts/arm/st/f3/stm32f3.dtsi:441 */
	usb_fs_phy: usbphy {
		compatible = "usb-nop-xceiv"; /* in zephyr/dts/arm/st/f3/stm32f3.dtsi:442 */
		#phy-cells = < 0x0 >;         /* in zephyr/dts/arm/st/f3/stm32f3.dtsi:443 */
		phandle = < 0x14 >;           /* in zephyr/dts/arm/st/f3/stm32f3.dtsi:265 */
	};

	/* node '/smbus1' defined in zephyr/dts/arm/st/f3/stm32f3.dtsi:446 */
	smbus1: smbus1 {
		compatible = "st,stm32-smbus"; /* in zephyr/dts/arm/st/f3/stm32f3.dtsi:447 */
		#address-cells = < 0x1 >;      /* in zephyr/dts/arm/st/f3/stm32f3.dtsi:448 */
		#size-cells = < 0x0 >;         /* in zephyr/dts/arm/st/f3/stm32f3.dtsi:449 */
		i2c = < &i2c1 >;               /* in zephyr/dts/arm/st/f3/stm32f3.dtsi:450 */
		status = "disabled";           /* in zephyr/dts/arm/st/f3/stm32f3.dtsi:451 */
	};

	/* node '/smbus2' defined in zephyr/dts/arm/st/f3/stm32f302.dtsi:130 */
	smbus2: smbus2 {
		compatible = "st,stm32-smbus"; /* in zephyr/dts/arm/st/f3/stm32f302.dtsi:131 */
		#address-cells = < 0x1 >;      /* in zephyr/dts/arm/st/f3/stm32f302.dtsi:132 */
		#size-cells = < 0x0 >;         /* in zephyr/dts/arm/st/f3/stm32f302.dtsi:133 */
		i2c = < &i2c2 >;               /* in zephyr/dts/arm/st/f3/stm32f302.dtsi:134 */
		status = "disabled";           /* in zephyr/dts/arm/st/f3/stm32f302.dtsi:135 */
	};

	/* node '/leds' defined in zephyr/boards/seco/stm32f3_seco_d23/stm32f3_seco_d23.dts:24 */
	leds {
		compatible = "gpio-leds"; /* in zephyr/boards/seco/stm32f3_seco_d23/stm32f3_seco_d23.dts:25 */

		/* node '/leds/led_1' defined in zephyr/boards/seco/stm32f3_seco_d23/stm32f3_seco_d23.dts:27 */
		led_1: led_1 {
			gpios = < &gpiod 0x8 0x0 >; /* in zephyr/boards/seco/stm32f3_seco_d23/stm32f3_seco_d23.dts:28 */
			label = "LED-1";            /* in zephyr/boards/seco/stm32f3_seco_d23/stm32f3_seco_d23.dts:29 */
		};

		/* node '/leds/led_2' defined in zephyr/boards/seco/stm32f3_seco_d23/stm32f3_seco_d23.dts:32 */
		led_2: led_2 {
			gpios = < &gpiod 0x9 0x0 >; /* in zephyr/boards/seco/stm32f3_seco_d23/stm32f3_seco_d23.dts:33 */
			label = "LED-2";            /* in zephyr/boards/seco/stm32f3_seco_d23/stm32f3_seco_d23.dts:34 */
		};
	};

	/* node '/3p3v-out-pwr-ctrl' defined in zephyr/boards/seco/stm32f3_seco_d23/stm32f3_seco_d23.dts:38 */
	out_3p3v_pwr: 3p3v-out-pwr-ctrl {
		compatible = "regulator-fixed";       /* in zephyr/boards/seco/stm32f3_seco_d23/stm32f3_seco_d23.dts:39 */
		regulator-name = "3p3v-out-pwr-ctrl"; /* in zephyr/boards/seco/stm32f3_seco_d23/stm32f3_seco_d23.dts:40 */
		enable-gpios = < &gpioe 0x7 0x0 >;    /* in zephyr/boards/seco/stm32f3_seco_d23/stm32f3_seco_d23.dts:41 */
		regulator-always-on;                  /* in zephyr/boards/seco/stm32f3_seco_d23/stm32f3_seco_d23.dts:42 */
		regulator-boot-on;                    /* in zephyr/boards/seco/stm32f3_seco_d23/stm32f3_seco_d23.dts:43 */
		status = "okay";                      /* in zephyr/boards/seco/stm32f3_seco_d23/stm32f3_seco_d23.dts:44 */
	};

	/* node '/out-gpio-bufa-pwr-ctrl' defined in zephyr/boards/seco/stm32f3_seco_d23/stm32f3_seco_d23.dts:47 */
	out_gpio_bufa_pwr: out-gpio-bufa-pwr-ctrl {
		compatible = "regulator-fixed";            /* in zephyr/boards/seco/stm32f3_seco_d23/stm32f3_seco_d23.dts:48 */
		regulator-name = "out-gpio-bufa-pwr-ctrl"; /* in zephyr/boards/seco/stm32f3_seco_d23/stm32f3_seco_d23.dts:49 */
		enable-gpios = < &gpiof 0x2 0x1 >;         /* in zephyr/boards/seco/stm32f3_seco_d23/stm32f3_seco_d23.dts:50 */
		regulator-boot-on;                         /* in zephyr/boards/seco/stm32f3_seco_d23/stm32f3_seco_d23.dts:51 */
		status = "okay";                           /* in zephyr/boards/seco/stm32f3_seco_d23/stm32f3_seco_d23.dts:52 */
	};

	/* node '/out-gpio-bufb-pwr-ctrl' defined in zephyr/boards/seco/stm32f3_seco_d23/stm32f3_seco_d23.dts:55 */
	out_gpio_bufb_pwr: out-gpio-bufb-pwr-ctrl {
		compatible = "regulator-fixed";            /* in zephyr/boards/seco/stm32f3_seco_d23/stm32f3_seco_d23.dts:56 */
		regulator-name = "out-gpio-bufb-pwr-ctrl"; /* in zephyr/boards/seco/stm32f3_seco_d23/stm32f3_seco_d23.dts:57 */
		enable-gpios = < &gpiof 0x4 0x1 >;         /* in zephyr/boards/seco/stm32f3_seco_d23/stm32f3_seco_d23.dts:58 */
		regulator-boot-on;                         /* in zephyr/boards/seco/stm32f3_seco_d23/stm32f3_seco_d23.dts:59 */
		status = "okay";                           /* in zephyr/boards/seco/stm32f3_seco_d23/stm32f3_seco_d23.dts:60 */
	};

	/* node '/in-gpio-buf-pwr-ctrl' defined in zephyr/boards/seco/stm32f3_seco_d23/stm32f3_seco_d23.dts:63 */
	in_gpio_buf_pwr: in-gpio-buf-pwr-ctrl {
		compatible = "regulator-fixed";          /* in zephyr/boards/seco/stm32f3_seco_d23/stm32f3_seco_d23.dts:64 */
		regulator-name = "in-gpio-buf-pwr-ctrl"; /* in zephyr/boards/seco/stm32f3_seco_d23/stm32f3_seco_d23.dts:65 */
		enable-gpios = < &gpiof 0x6 0x1 >;       /* in zephyr/boards/seco/stm32f3_seco_d23/stm32f3_seco_d23.dts:66 */
		regulator-boot-on;                       /* in zephyr/boards/seco/stm32f3_seco_d23/stm32f3_seco_d23.dts:67 */
		status = "okay";                         /* in zephyr/boards/seco/stm32f3_seco_d23/stm32f3_seco_d23.dts:68 */
	};

	/* node '/can-phy0' defined in zephyr/boards/seco/stm32f3_seco_d23/stm32f3_seco_d23.dts:71 */
	transceiver0: can-phy0 {
		compatible = "nxp,tja1040",
		             "can-transceiver-gpio"; /* in zephyr/boards/seco/stm32f3_seco_d23/stm32f3_seco_d23.dts:72 */
		standby-gpios = < &gpiod 0x0 0x0 >;  /* in zephyr/boards/seco/stm32f3_seco_d23/stm32f3_seco_d23.dts:73 */
		max-bitrate = < 0xf4240 >;           /* in zephyr/boards/seco/stm32f3_seco_d23/stm32f3_seco_d23.dts:74 */
		#phy-cells = < 0x0 >;                /* in zephyr/boards/seco/stm32f3_seco_d23/stm32f3_seco_d23.dts:75 */
		phandle = < 0x19 >;                  /* in zephyr/boards/seco/stm32f3_seco_d23/stm32f3_seco_d23.dts:182 */
	};
};
